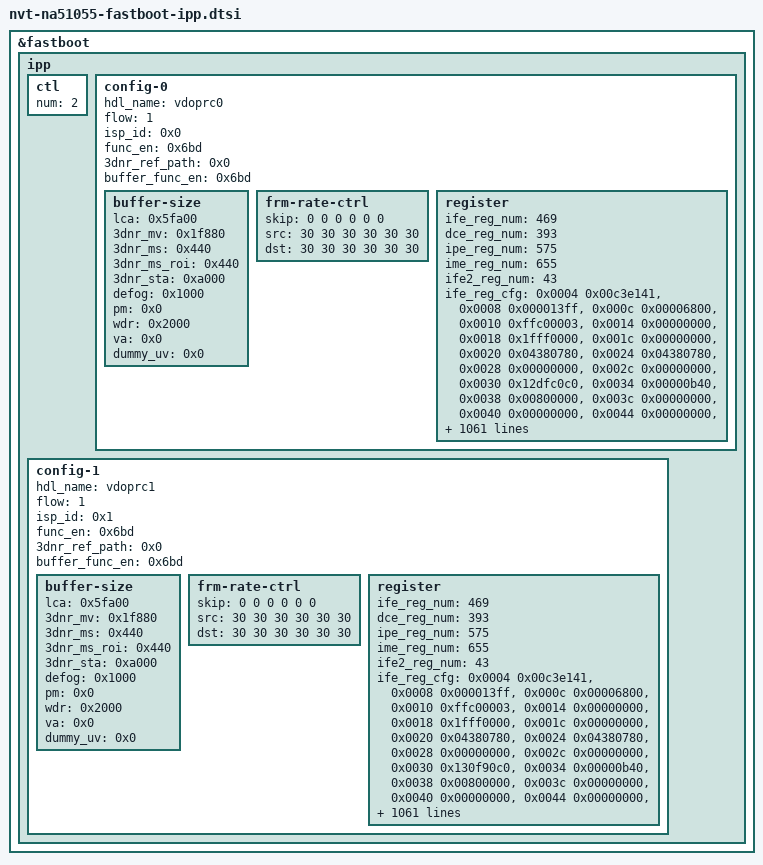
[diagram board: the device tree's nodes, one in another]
&fastboot {
	ipp {
		ctl {
			num = <2>;
		};
		config-0 {
			hdl_name = "vdoprc0";
			flow = <1>;
			isp_id = <0x0>;
			func_en = <0x6bd>;
			3dnr_ref_path = <0x0>;
			buffer_func_en = <0x6bd>;
			buffer-size {
				lca = <0x5fa00>;
				3dnr_mv = <0x1f880>;
				3dnr_ms = <0x440>;
				3dnr_ms_roi = <0x440>;
				3dnr_sta = <0xa000>;
				defog = <0x1000>;
				pm = <0x0>;
				wdr = <0x2000>;
				va = <0x0>;
				dummy_uv = <0x0>;
			};
			frm-rate-ctrl {
				skip = <0 0 0 0 0 0>;
				src = <30 30 30 30 30 30>;
				dst = <30 30 30 30 30 30>;
			};
			register {
			  ife_reg_num = <469>;
			  dce_reg_num = <393>;
			  ipe_reg_num = <575>;
			  ime_reg_num = <655>;
			  ife2_reg_num = <43>;

			  ife_reg_cfg = 
			    <0x0004 0x00c3e141>,
			    <0x0008 0x000013ff>,
			    <0x000c 0x00006800>,
			    <0x0010 0xffc00003>,
			    <0x0014 0x00000000>,
			    <0x0018 0x1fff0000>,
			    <0x001c 0x00000000>,
			    <0x0020 0x04380780>,
			    <0x0024 0x04380780>,
			    <0x0028 0x00000000>,
			    <0x002c 0x00000000>,
			    <0x0030 0x12dfc0c0>,
			    <0x0034 0x00000b40>,
			    <0x0038 0x00800000>,
			    <0x003c 0x00000000>,
			    <0x0040 0x00000000>,
			    <0x0044 0x00000000>,
			    <0x0048 0x00000000>,
			    <0x004c 0x00000000>,
			    <0x0050 0x00000000>,
			    <0x0054 0x00800000>,
			    <0x0058 0x00000000>,
			    <0x005c 0x00001000>,
			    <0x0060 0x00000000>,
			    <0x0064 0x00000000>,
			    <0x0068 0x00000000>,
			    <0x006c 0x00000000>,
			    <0x0070 0x000fff08>,
			    <0x0074 0x01120214>,
			    <0x0078 0x027b0112>,
			    <0x007c 0x00000112>,
			    <0x0080 0x00800080>,
			    <0x0084 0x00800080>,
			    <0x0088 0x00000080>,
			    <0x008c 0x00800080>,
			    <0x0090 0x00800080>,
			    <0x0094 0x00000080>,
			    <0x0098 0x00000000>,
			    <0x009c 0x00000000>,
			    <0x00a0 0x00000000>,
			    <0x00a4 0x00000000>,
			    <0x00a8 0x00000000>,
			    <0x00ac 0x00000000>,
			    <0x00b0 0x01000100>,
			    <0x00b4 0x01000100>,
			    <0x00b8 0x00000100>,
			    <0x00bc 0x00000000>,
			    <0x00c0 0x00000000>,
			    <0x00c4 0x00000000>,
			    <0x00c8 0x00000000>,
			    <0x00cc 0x00000000>,
			    <0x00d0 0x00000000>,
			    <0x00d4 0x00000000>,
			    <0x00d8 0x00000000>,
			    <0x00dc 0x00000000>,
			    <0x00e0 0x00000000>,
			    <0x00e4 0x00000000>,
			    <0x00e8 0x00000000>,
			    <0x00ec 0x00000000>,
			    <0x00f0 0x00000000>,
			    <0x00f4 0x00000000>,
			    <0x00f8 0x00000000>,
			    <0x00fc 0x00000000>,
			    <0x0100 0x00080040>,
			    <0x0104 0x00501200>,
			    <0x0108 0x0911171f>,
			    <0x010c 0x00000307>,
			    <0x0110 0x00010000>,
			    <0x0114 0x00020001>,
			    <0x0118 0x00030002>,
			    <0x011c 0x00000000>,
			    <0x0120 0x00010000>,
			    <0x0124 0x00020001>,
			    <0x0128 0x00030002>,
			    <0x012c 0x00000000>,
			    <0x0130 0x00010000>,
			    <0x0134 0x00020001>,
			    <0x0138 0x00030002>,
			    <0x013c 0x00000000>,
			    <0x0140 0x00010000>,
			    <0x0144 0x00020001>,
			    <0x0148 0x00030002>,
			    <0x014c 0x00000000>,
			    <0x0150 0x00020000>,
			    <0x0154 0x00040002>,
			    <0x0158 0x00060004>,
			    <0x015c 0x00000000>,
			    <0x0160 0x00020000>,
			    <0x0164 0x00040002>,
			    <0x0168 0x00060004>,
			    <0x016c 0x00000000>,
			    <0x0170 0x00020000>,
			    <0x0174 0x00040002>,
			    <0x0178 0x00060004>,
			    <0x017c 0x00000000>,
			    <0x0180 0x00020000>,
			    <0x0184 0x00040002>,
			    <0x0188 0x00060004>,
			    <0x018c 0x00000000>,
			    <0x0190 0x002c62c6>,
			    <0x0194 0x0040c40c>,
			    <0x0198 0x006af6af>,
			    <0x019c 0x0093d93d>,
			    <0x01a0 0x00f41f41>,
			    <0x01a4 0x00010000>,
			    <0x01a8 0x00010033>,
			    <0x01ac 0x86543210>,
			    <0x01b0 0x86543210>,
			    <0x01b4 0x00f00001>,
			    <0x01b8 0x008000a0>,
			    <0x01bc 0x000010ff>,
			    <0x01c0 0x00020000>,
			    <0x01c4 0x00030002>,
			    <0x01c8 0x00040004>,
			    <0x01cc 0x00050004>,
			    <0x01d0 0x00060005>,
			    <0x01d4 0x00060006>,
			    <0x01d8 0x00070006>,
			    <0x01dc 0x00070007>,
			    <0x01e0 0x00000008>,
			    <0x01e4 0x00020000>,
			    <0x01e8 0x00030002>,
			    <0x01ec 0x00040004>,
			    <0x01f0 0x00050004>,
			    <0x01f4 0x00060005>,
			    <0x01f8 0x00060006>,
			    <0x01fc 0x00070006>,
			    <0x0200 0x00070007>,
			    <0x0204 0x00000008>,
			    <0x0208 0x00020000>,
			    <0x020c 0x00030002>,
			    <0x0210 0x00040004>,
			    <0x0214 0x00050004>,
			    <0x0218 0x00060005>,
			    <0x021c 0x00060006>,
			    <0x0220 0x00070006>,
			    <0x0224 0x00070007>,
			    <0x0228 0x00000008>,
			    <0x022c 0x00020000>,
			    <0x0230 0x00030002>,
			    <0x0234 0x00040004>,
			    <0x0238 0x00050004>,
			    <0x023c 0x00060005>,
			    <0x0240 0x00060006>,
			    <0x0244 0x00070006>,
			    <0x0248 0x00070007>,
			    <0x024c 0x00000008>,
			    <0x0250 0x00040000>,
			    <0x0254 0x00060004>,
			    <0x0258 0x00080008>,
			    <0x025c 0x000a0008>,
			    <0x0260 0x000c000a>,
			    <0x0264 0x000c000c>,
			    <0x0268 0x000e000c>,
			    <0x026c 0x000e000e>,
			    <0x0270 0x00000010>,
			    <0x0274 0x00040000>,
			    <0x0278 0x00060004>,
			    <0x027c 0x00080008>,
			    <0x0280 0x000a0008>,
			    <0x0284 0x000c000a>,
			    <0x0288 0x000c000c>,
			    <0x028c 0x000e000c>,
			    <0x0290 0x000e000e>,
			    <0x0294 0x00000010>,
			    <0x0298 0x00040000>,
			    <0x029c 0x00060004>,
			    <0x02a0 0x00080008>,
			    <0x02a4 0x000a0008>,
			    <0x02a8 0x000c000a>,
			    <0x02ac 0x000c000c>,
			    <0x02b0 0x000e000c>,
			    <0x02b4 0x000e000e>,
			    <0x02b8 0x00000010>,
			    <0x02bc 0x00040000>,
			    <0x02c0 0x00060004>,
			    <0x02c4 0x00080008>,
			    <0x02c8 0x000a0008>,
			    <0x02cc 0x000c000a>,
			    <0x02d0 0x000c000c>,
			    <0x02d4 0x000e000c>,
			    <0x02d8 0x000e000e>,
			    <0x02dc 0x00000010>,
			    <0x02e0 0x021c03c0>,
			    <0x02e4 0x021c03c0>,
			    <0x02e8 0x021c03c0>,
			    <0x02ec 0x021c03c0>,
			    <0x02f0 0x003b73b8>,
			    <0x02f4 0x00000001>,
			    <0x02f8 0x00000000>,
			    <0x02fc 0x00000000>,
			    <0x0300 0x00000000>,
			    <0x0304 0x00000000>,
			    <0x0308 0x00000000>,
			    <0x030c 0x00000000>,
			    <0x0310 0x00000000>,
			    <0x0314 0x00000000>,
			    <0x0318 0x00000000>,
			    <0x031c 0x00000000>,
			    <0x0320 0x00000000>,
			    <0x0324 0x00000000>,
			    <0x0328 0x00000000>,
			    <0x032c 0x00000000>,
			    <0x0330 0x00000000>,
			    <0x0334 0x00000000>,
			    <0x0338 0x00000000>,
			    <0x033c 0x00000000>,
			    <0x0340 0x00000000>,
			    <0x0344 0x00000000>,
			    <0x0348 0x00000000>,
			    <0x034c 0x00000000>,
			    <0x0350 0x00000000>,
			    <0x0354 0x00000000>,
			    <0x0358 0x00000000>,
			    <0x035c 0x00000000>,
			    <0x0360 0x00000000>,
			    <0x0364 0x00000000>,
			    <0x0368 0x00000000>,
			    <0x036c 0x00000000>,
			    <0x0370 0x00000000>,
			    <0x0374 0x00000000>,
			    <0x0378 0x00000000>,
			    <0x037c 0x00000000>,
			    <0x0380 0x00000000>,
			    <0x0384 0x00000000>,
			    <0x0388 0x09060301>,
			    <0x038c 0x15120f0d>,
			    <0x0390 0x211e1b18>,
			    <0x0394 0x2d2a2724>,
			    <0x0398 0x00000030>,
			    <0x039c 0x1b181000>,
			    <0x03a0 0x1f1e1c1b>,
			    <0x03a4 0x1c1d1e1f>,
			    <0x03a8 0x0c1a1b1c>,
			    <0x03ac 0x00000004>,
			    <0x03b0 0x00000000>,
			    <0x03b4 0x00000000>,
			    <0x03b8 0x00000000>,
			    <0x03bc 0x00000000>,
			    <0x03c0 0x1f1f1f1f>,
			    <0x03c4 0x1e1e1f1f>,
			    <0x03c8 0x14181c1d>,
			    <0x03cc 0x080a0c10>,
			    <0x03d0 0x06060606>,
			    <0x03d4 0x05050505>,
			    <0x03d8 0x04040404>,
			    <0x03dc 0x20010203>,
			    <0x03e0 0x00000000>,
			    <0x03e4 0x00000000>,
			    <0x03e8 0x00000000>,
			    <0x03ec 0x00000000>,
			    <0x03f0 0x00000000>,
			    <0x03f4 0x00000000>,
			    <0x03f8 0x00000000>,
			    <0x03fc 0x00000000>,
			    <0x0400 0x00000000>,
			    <0x0404 0x00000000>,
			    <0x0408 0x00000000>,
			    <0x040c 0x01000000>,
			    <0x0410 0x00000000>,
			    <0x0414 0x00000000>,
			    <0x0418 0x00000000>,
			    <0x041c 0x01000000>,
			    <0x0420 0x00000000>,
			    <0x0424 0x00000000>,
			    <0x0428 0x00000000>,
			    <0x042c 0x00000000>,
			    <0x0430 0x00000000>,
			    <0x0434 0x00000000>,
			    <0x0438 0x00000000>,
			    <0x043c 0x00000000>,
			    <0x0440 0x00000000>,
			    <0x0444 0x00000000>,
			    <0x0448 0x00000000>,
			    <0x044c 0x00000000>,
			    <0x0450 0x00000000>,
			    <0x0454 0x00000000>,
			    <0x0458 0x00000000>,
			    <0x045c 0x00000000>,
			    <0x0460 0x00000000>,
			    <0x0464 0x00000000>,
			    <0x0468 0x00000000>,
			    <0x046c 0x00000000>,
			    <0x0470 0x00000000>,
			    <0x0474 0x00000000>,
			    <0x0478 0x00000000>,
			    <0x047c 0x00000000>,
			    <0x0480 0x00000000>,
			    <0x0484 0x00000000>,
			    <0x0488 0x00000000>,
			    <0x048c 0x00000000>,
			    <0x0490 0x00000000>,
			    <0x0494 0x00000000>,
			    <0x0498 0x00000000>,
			    <0x049c 0x00000000>,
			    <0x04a0 0x00000000>,
			    <0x04a4 0x00000000>,
			    <0x04a8 0x00000000>,
			    <0x04ac 0x00000000>,
			    <0x04b0 0x00000000>,
			    <0x04b4 0x00000000>,
			    <0x04b8 0x00000000>,
			    <0x04bc 0x00000000>,
			    <0x04c0 0x00000000>,
			    <0x04c4 0x00000000>,
			    <0x04c8 0x00000000>,
			    <0x04cc 0x00000000>,
			    <0x04d0 0x00000000>,
			    <0x04d4 0x00000000>,
			    <0x04d8 0x00000000>,
			    <0x04dc 0x00000000>,
			    <0x04e0 0x00000000>,
			    <0x04e4 0x00000000>,
			    <0x04e8 0x00000000>,
			    <0x04ec 0x00000000>,
			    <0x04f0 0x00000000>,
			    <0x04f4 0x00000000>,
			    <0x04f8 0x00000000>,
			    <0x04fc 0x00000000>,
			    <0x0500 0x00000000>,
			    <0x0504 0x00000000>,
			    <0x0508 0x00000000>,
			    <0x050c 0x00000000>,
			    <0x0510 0x00000000>,
			    <0x0514 0x00000000>,
			    <0x0518 0x00000000>,
			    <0x051c 0x00000000>,
			    <0x0520 0x00000000>,
			    <0x0524 0x00000000>,
			    <0x0528 0x00000000>,
			    <0x052c 0x00000000>,
			    <0x0530 0x00000000>,
			    <0x0534 0x00000000>,
			    <0x0538 0x00000000>,
			    <0x053c 0x00000000>,
			    <0x0540 0x00000000>,
			    <0x0544 0x00000000>,
			    <0x0548 0x00000000>,
			    <0x054c 0x00000000>,
			    <0x0550 0x00100210>,
			    <0x0554 0x0e009c00>,
			    <0x0558 0x810060c0>,
			    <0x055c 0x0e009c00>,
			    <0x0560 0x810060c0>,
			    <0x0564 0x00000000>,
			    <0x0568 0x00000000>,
			    <0x056c 0x00000000>,
			    <0x0570 0x00000100>,
			    <0x0574 0x18a41040>,
			    <0x0578 0x10a63a0e>,
			    <0x057c 0x00000886>,
			    <0x0580 0x18a41040>,
			    <0x0584 0x10a63a0e>,
			    <0x0588 0x00000886>,
			    <0x058c 0x00000000>,
			    <0x0590 0xff100fff>,
			    <0x0594 0xff100fff>,
			    <0x0598 0x00000000>,
			    <0x059c 0x00000000>,
			    <0x05a0 0x00400010>,
			    <0x05a4 0x00000100>,
			    <0x05a8 0x00400000>,
			    <0x05ac 0x04000100>,
			    <0x05b0 0x00002222>,
			    <0x05b4 0x00000000>,
			    <0x05b8 0x00000000>,
			    <0x05bc 0x00000000>,
			    <0x05c0 0x00000000>,
			    <0x05c4 0x00000000>,
			    <0x05c8 0x00000000>,
			    <0x05cc 0x00000000>,
			    <0x05d0 0x00000000>,
			    <0x05d4 0x00000000>,
			    <0x05d8 0x00000000>,
			    <0x05dc 0x00000000>,
			    <0x05e0 0x00000000>,
			    <0x05e4 0x00000000>,
			    <0x05e8 0x00000000>,
			    <0x05ec 0x00000000>,
			    <0x05f0 0x00000000>,
			    <0x05f4 0x00000000>,
			    <0x05f8 0x00000000>,
			    <0x05fc 0x00000000>,
			    <0x0600 0x00000004>,
			    <0x0604 0xffffffff>,
			    <0x0608 0x80a0c0e0>,
			    <0x060c 0x10204060>,
			    <0x0610 0x00000000>,
			    <0x0614 0x00000000>,
			    <0x0618 0x06040200>,
			    <0x061c 0x0e0c0a08>,
			    <0x0620 0x16141210>,
			    <0x0624 0x1e1c1a18>,
			    <0x0628 0x26242220>,
			    <0x062c 0x2e2c2a28>,
			    <0x0630 0x36343230>,
			    <0x0634 0x3e3c3a38>,
			    <0x0638 0x55555555>,
			    <0x063c 0x55555555>,
			    <0x0640 0x03430000>,
			    <0x0644 0x060604e9>,
			    <0x0648 0x078b06de>,
			    <0x064c 0x0898081c>,
			    <0x0650 0x09670905>,
			    <0x0654 0x0a0e09be>,
			    <0x0658 0x0a9b0a57>,
			    <0x065c 0x0b140ad9>,
			    <0x0660 0x0b7f0b4b>,
			    <0x0664 0x0bde0bb0>,
			    <0x0668 0x0c340c0a>,
			    <0x066c 0x0c830c5c>,
			    <0x0670 0x0ccb0ca8>,
			    <0x0674 0x0d0d0ced>,
			    <0x0678 0x0d4b0d2d>,
			    <0x067c 0x0d850d69>,
			    <0x0680 0x0dbc0da1>,
			    <0x0684 0x0def0dd6>,
			    <0x0688 0x0e200e08>,
			    <0x068c 0x0e4e0e37>,
			    <0x0690 0x0e790e64>,
			    <0x0694 0x0ea30e8e>,
			    <0x0698 0x0ecb0eb7>,
			    <0x069c 0x0ef10ede>,
			    <0x06a0 0x0f150f03>,
			    <0x06a4 0x0f380f27>,
			    <0x06a8 0x0f5a0f49>,
			    <0x06ac 0x0f7a0f6a>,
			    <0x06b0 0x0f9a0f8a>,
			    <0x06b4 0x0fb80fa9>,
			    <0x06b8 0x0fd50fc7>,
			    <0x06bc 0x0ff20fe4>,
			    <0x06c0 0x00000fff>,
			    <0x06c4 0x00000000>,
			    <0x06c8 0x00000000>,
			    <0x06cc 0x00000000>,
			    <0x06d0 0x00000000>,
			    <0x06d4 0x00000000>,
			    <0x06d8 0x00000000>,
			    <0x06dc 0x00000000>,
			    <0x06e0 0x00000000>,
			    <0x06e4 0x00000000>,
			    <0x06e8 0x00000000>,
			    <0x06ec 0x00000000>,
			    <0x06f0 0x00000000>,
			    <0x06f4 0x00000000>,
			    <0x06f8 0x00000000>,
			    <0x06fc 0x00000000>,
			    <0x0700 0x00000011>,
			    <0x0704 0x0c080400>,
			    <0x0708 0x1c181410>,
			    <0x070c 0x0002aaaa>,
			    <0x0710 0x0002aaaa>,
			    <0x0714 0x00200000>,
			    <0x0718 0x00600040>,
			    <0x071c 0x00a00080>,
			    <0x0720 0x00e000c0>,
			    <0x0724 0x01440100>,
			    <0x0728 0x01e40190>,
			    <0x072c 0x02a40240>,
			    <0x0730 0x03840310>,
			    <0x0734 0x04840400>,
			    <0x0738 0x05a40510>,
			    <0x073c 0x06e40640>,
			    <0x0740 0x08440790>,
			    <0x0744 0x09c40900>,
			    <0x0748 0x0b640a90>,
			    <0x074c 0x0d240c40>,
			    <0x0750 0x0f040e10>,
			    <0x0754 0x00000fff>;

			  dce_reg_cfg = 
			    <0x0004 0x00004614>,
			    <0x0008 0x00001fdf>,
			    <0x000c 0x00000000>,
			    <0x0010 0x04380780>,
			    <0x0014 0x00000000>,
			    <0x0018 0x00000010>,
			    <0x001c 0x00400000>,
			    <0x0020 0x00400000>,
			    <0x0024 0x00000780>,
			    <0x0028 0x00400000>,
			    <0x002c 0x00000780>,
			    <0x0030 0x00400000>,
			    <0x0034 0x00000780>,
			    <0x0038 0x00400000>,
			    <0x003c 0x00000780>,
			    <0x0040 0x00000021>,
			    <0x0044 0x11244912>,
			    <0x0048 0x11244912>,
			    <0x004c 0x0f23c912>,
			    <0x0050 0x0f23c8f2>,
			    <0x0054 0x0f23c8f2>,
			    <0x0058 0x000000f2>,
			    <0x005c 0x7f340000>,
			    <0x0060 0x00000000>,
			    <0x0064 0x044f0000>,
			    <0x0068 0x044f0000>,
			    <0x006c 0x00000012>,
			    <0x0070 0x00000000>,
			    <0x0074 0x00000000>,
			    <0x0078 0x00000000>,
			    <0x007c 0x00000000>,
			    <0x0080 0x00000000>,
			    <0x0084 0x00000000>,
			    <0x0088 0x00000000>,
			    <0x008c 0x00000780>,
			    <0x0090 0x00000000>,
			    <0x0094 0x00000000>,
			    <0x0098 0x00000000>,
			    <0x009c 0x00000000>,
			    <0x00a0 0x00000000>,
			    <0x00a4 0x00400000>,
			    <0x00a8 0x2c0003c0>,
			    <0x00ac 0x000a0028>,
			    <0x00b0 0x80000000>,
			    <0x00b4 0x00000000>,
			    <0x00b8 0xf8888888>,
			    <0x00bc 0x485f7880>,
			    <0x00c0 0x2428303a>,
			    <0x00c4 0x20202020>,
			    <0x00c8 0x20202020>,
			    <0x00cc 0x00a00020>,
			    <0x00d0 0x00014008>,
			    <0x00d4 0x122347ff>,
			    <0x00d8 0x00000111>,
			    <0x00dc 0x00000000>,
			    <0x00e0 0x40081007>,
			    <0x00e4 0x00408003>,
			    <0x00e8 0x00cc00cc>,
			    <0x00ec 0xa80080e6>,
			    <0x00f0 0x00800080>,
			    <0x00f4 0x00010080>,
			    <0x00f8 0x00000100>,
			    <0x00fc 0xffffe0c0>,
			    <0x0100 0x00000000>,
			    <0x0104 0x00000000>,
			    <0x0108 0x00000000>,
			    <0x010c 0x00000000>,
			    <0x0110 0x00000000>,
			    <0x0114 0x00000000>,
			    <0x0118 0x00000000>,
			    <0x011c 0x00000000>,
			    <0x0120 0x0000023f>,
			    <0x0124 0x16240600>,
			    <0x0128 0x00000100>,
			    <0x012c 0x16242600>,
			    <0x0130 0x00000100>,
			    <0x0134 0x04080422>,
			    <0x0138 0x0f79cc3b>,
			    <0x013c 0x0fde1c3b>,
			    <0x0140 0x00000000>,
			    <0x0144 0x00000000>,
			    <0x0148 0x00000000>,
			    <0x014c 0x00000000>,
			    <0x0150 0x00000000>,
			    <0x0154 0x20000000>,
			    <0x0158 0x00000054>,
			    <0x015c 0x1565193c>,
			    <0x0160 0x160c160c>,
			    <0x0164 0x05030003>,
			    <0x0168 0x00000000>,
			    <0x016c 0x00000000>,
			    <0x0170 0x00000000>,
			    <0x0174 0x00000000>,
			    <0x0178 0x00000000>,
			    <0x017c 0x00000000>,
			    <0x0180 0x00000000>,
			    <0x0184 0x00000000>,
			    <0x0188 0x00000000>,
			    <0x018c 0x00000000>,
			    <0x0190 0x00000000>,
			    <0x0194 0x00000000>,
			    <0x0198 0x00000000>,
			    <0x019c 0x00000000>,
			    <0x01a0 0x00000000>,
			    <0x01a4 0x00000000>,
			    <0x01a8 0x00000000>,
			    <0x01ac 0x00000000>,
			    <0x01b0 0x00000000>,
			    <0x01b4 0x00000000>,
			    <0x01b8 0x00000000>,
			    <0x01bc 0x00000000>,
			    <0x01c0 0x00000000>,
			    <0x01c4 0x00000000>,
			    <0x01c8 0x00000000>,
			    <0x01cc 0x00000000>,
			    <0x01d0 0x00000000>,
			    <0x01d4 0x00000000>,
			    <0x01d8 0x00000000>,
			    <0x01dc 0x00000000>,
			    <0x01e0 0x00000000>,
			    <0x01e4 0x00000000>,
			    <0x01e8 0x00000000>,
			    <0x01ec 0x00000000>,
			    <0x01f0 0x00000000>,
			    <0x01f4 0x00000000>,
			    <0x01f8 0x00000000>,
			    <0x01fc 0x00000000>,
			    <0x0200 0x00000000>,
			    <0x0204 0x00000000>,
			    <0x0208 0x00000000>,
			    <0x020c 0x00000000>,
			    <0x0210 0x00000000>,
			    <0x0214 0x18100800>,
			    <0x0218 0x2624201c>,
			    <0x021c 0x2b2a2928>,
			    <0x0220 0x2f2e2d2c>,
			    <0x0224 0x33323130>,
			    <0x0228 0x37363534>,
			    <0x022c 0x3b3a3938>,
			    <0x0230 0x3f3e3d3c>,
			    <0x0234 0x00005abf>,
			    <0x0238 0x00000000>,
			    <0x023c 0x0ff70fff>,
			    <0x0240 0x0fa10fd8>,
			    <0x0244 0x0ef10f54>,
			    <0x0248 0x0df70e7b>,
			    <0x024c 0x0cd10d68>,
			    <0x0250 0x0b9d0c37>,
			    <0x0254 0x0a700b04>,
			    <0x0258 0x095909e1>,
			    <0x025c 0x085f08d8>,
			    <0x0260 0x078407ee>,
			    <0x0264 0x06c70722>,
			    <0x0268 0x06240673>,
			    <0x026c 0x055c05dc>,
			    <0x0270 0x049004ee>,
			    <0x0274 0x03f9043f>,
			    <0x0278 0x038803bd>,
			    <0x027c 0x0332035b>,
			    <0x0280 0x02f0030f>,
			    <0x0284 0x02a602d4>,
			    <0x0288 0x02620280>,
			    <0x028c 0x02230249>,
			    <0x0290 0x01f30208>,
			    <0x0294 0x01d801e4>,
			    <0x0298 0x01c801cf>,
			    <0x029c 0x01bd01c2>,
			    <0x02a0 0x01b501b9>,
			    <0x02a4 0x01b001b2>,
			    <0x02a8 0x01ac01ae>,
			    <0x02ac 0x01a901aa>,
			    <0x02b0 0x01a601a7>,
			    <0x02b4 0x01a401a5>,
			    <0x02b8 0x01a301a4>,
			    <0x02bc 0x000001a2>,
			    <0x02c0 0x00008040>,
			    <0x02c4 0xffff0000>,
			    <0x02c8 0x00000000>,
			    <0x02cc 0x00000000>,
			    <0x02d0 0x00000000>,
			    <0x02d4 0x79420000>,
			    <0x02d8 0x6ffcbb81>,
			    <0x02dc 0xb14f698a>,
			    <0x02e0 0xb79eb2e2>,
			    <0x02e4 0x92217cf2>,
			    <0x02e8 0x6d6369e8>,
			    <0x02ec 0x64d75e86>,
			    <0x02f0 0x6e7d641f>,
			    <0x02f4 0xa7c59e69>,
			    <0x02f8 0x9064c26e>,
			    <0x02fc 0x5a11634c>,
			    <0x0300 0x4e5c54cc>,
			    <0x0304 0x57365098>,
			    <0x0308 0x4d795284>,
			    <0x030c 0x591a4c7a>,
			    <0x0310 0x5ad85ff0>,
			    <0x0314 0x58d05719>,
			    <0x0318 0x565655c9>,
			    <0x031c 0x544e57b1>,
			    <0x0320 0x530257ca>,
			    <0x0324 0x4a054b4d>,
			    <0x0328 0x5c71539f>,
			    <0x032c 0x5e6267d3>,
			    <0x0330 0x737d64dc>,
			    <0x0334 0x5ff57876>,
			    <0x0338 0x472d4c5e>,
			    <0x033c 0x44e54e0b>,
			    <0x0340 0x401d3e8d>,
			    <0x0344 0x45df4627>,
			    <0x0348 0x2e1539c8>,
			    <0x034c 0x2409264a>,
			    <0x0350 0x24d125c6>,
			    <0x0354 0x260b23de>,
			    <0x0358 0x2b4029ba>,
			    <0x035c 0x2db32cc5>,
			    <0x0360 0x342d2c04>,
			    <0x0364 0x432d3a45>,
			    <0x0368 0x53c753ac>,
			    <0x036c 0x4f1347b3>,
			    <0x0370 0x5788573a>,
			    <0x0374 0x55856142>,
			    <0x0378 0x510f5229>,
			    <0x037c 0x3c904d84>,
			    <0x0380 0x2cb3312c>,
			    <0x0384 0x24a32969>,
			    <0x0388 0x18fe1f4e>,
			    <0x038c 0x16ff16ed>,
			    <0x0390 0x19e91902>,
			    <0x0394 0x1675182e>,
			    <0x0398 0x095c0f8f>,
			    <0x039c 0x06f6078e>,
			    <0x03a0 0x0561059e>,
			    <0x03a4 0x04a7053f>,
			    <0x03a8 0x044e0447>,
			    <0x03ac 0x0490046a>,
			    <0x03b0 0x041c04b3>,
			    <0x03b4 0x02fd0407>,
			    <0x03b8 0x02970274>,
			    <0x03bc 0x02510292>,
			    <0x03c0 0x025e0271>,
			    <0x03c4 0x02d0021f>,
			    <0x03c8 0x056b0365>,
			    <0x03cc 0x032f04ba>,
			    <0x03d0 0x1cac0441>,
			    <0x03d4 0x00000000>,
			    <0x03d8 0x00000000>,
			    <0x03dc 0x00000000>,
			    <0x03e0 0x00000000>,
			    <0x03e4 0x00000000>,
			    <0x03e8 0x00000000>,
			    <0x03ec 0x00000000>,
			    <0x03f0 0x00000000>,
			    <0x03f4 0x00000000>,
			    <0x03f8 0x00000000>,
			    <0x03fc 0x00000000>,
			    <0x0400 0x00000000>,
			    <0x0404 0x00000000>,
			    <0x0408 0x00ffffff>,
			    <0x040c 0x037415dd>,
			    <0x0410 0x00000000>,
			    <0x0414 0x00000000>,
			    <0x0418 0x10001000>,
			    <0x041c 0x00001000>,
			    <0x0420 0x00000000>,
			    <0x0424 0x00000000>,
			    <0x0428 0x00000000>,
			    <0x042c 0x00000000>,
			    <0x0430 0x00000000>,
			    <0x0434 0x00000000>,
			    <0x0438 0x00000000>,
			    <0x043c 0x00000000>,
			    <0x0440 0xfe0bffff>,
			    <0x0444 0xfa62fc2d>,
			    <0x0448 0xf704f8aa>,
			    <0x044c 0xf3e4f56d>,
			    <0x0450 0xf0fcf26a>,
			    <0x0454 0xee43ef9a>,
			    <0x0458 0xebb4ecf7>,
			    <0x045c 0xe94bea7b>,
			    <0x0460 0xe703e823>,
			    <0x0464 0xe4dae5eb>,
			    <0x0468 0xe2cbe3cf>,
			    <0x046c 0xe0d6e1ce>,
			    <0x0470 0xdef7dfe4>,
			    <0x0474 0xdd2cde0f>,
			    <0x0478 0xdb75dc4f>,
			    <0x047c 0xd9d0daa0>,
			    <0x0480 0xd83ad903>,
			    <0x0484 0xd6b4d775>,
			    <0x0488 0xd53cd5f6>,
			    <0x048c 0xd3d1d485>,
			    <0x0490 0xd272d320>,
			    <0x0494 0xd11fd1c7>,
			    <0x0498 0xcfd6d079>,
			    <0x049c 0xce98cf36>,
			    <0x04a0 0xcd63cdfc>,
			    <0x04a4 0xcc38cccc>,
			    <0x04a8 0xcb15cba5>,
			    <0x04ac 0xc9faca86>,
			    <0x04b0 0xc8e6c96f>,
			    <0x04b4 0xc7dac860>,
			    <0x04b8 0xc6d5c757>,
			    <0x04bc 0xc5d7c655>,
			    <0x04c0 0x0000c599>,
			    <0x04c4 0x00000000>,
			    <0x04c8 0x00000000>,
			    <0x04cc 0x00000000>,
			    <0x04d0 0x00000000>,
			    <0x04d4 0x00000000>,
			    <0x04d8 0x00000000>,
			    <0x04dc 0x00000000>,
			    <0x04e0 0x00000000>,
			    <0x04e4 0x00000000>,
			    <0x04e8 0x00000000>,
			    <0x04ec 0x00000000>,
			    <0x04f0 0x00000000>,
			    <0x04f4 0x00000000>,
			    <0x04f8 0x00000000>,
			    <0x04fc 0x00000000>,
			    <0x0500 0x00000000>,
			    <0x0504 0x00000000>,
			    <0x0508 0x00000000>,
			    <0x050c 0x00000000>,
			    <0x0510 0x00000000>,
			    <0x0514 0x00000000>,
			    <0x0518 0x00000000>,
			    <0x051c 0x00000000>,
			    <0x0520 0x00000000>,
			    <0x0524 0x00000000>,
			    <0x0528 0x00000000>,
			    <0x052c 0x00000000>,
			    <0x0530 0x00000000>,
			    <0x0534 0x00000000>,
			    <0x0538 0x00000000>,
			    <0x053c 0x00000000>,
			    <0x0540 0x00000000>,
			    <0x0544 0x00000000>,
			    <0x0548 0x00000000>,
			    <0x054c 0x00000000>,
			    <0x0550 0x00000000>,
			    <0x0554 0x00000000>,
			    <0x0558 0x00000000>,
			    <0x055c 0x00000000>,
			    <0x0560 0x00000000>,
			    <0x0564 0x00000000>,
			    <0x0568 0x00000000>,
			    <0x056c 0x00000000>,
			    <0x0570 0x00000000>,
			    <0x0574 0x00000000>,
			    <0x0578 0x00000000>,
			    <0x057c 0x00000000>,
			    <0x0580 0x00000000>,
			    <0x0584 0x00000000>,
			    <0x0588 0x00000000>,
			    <0x058c 0x00000000>,
			    <0x0590 0x00000000>,
			    <0x0594 0x00000000>,
			    <0x0598 0x00000000>,
			    <0x059c 0x00000000>,
			    <0x05a0 0x00000000>,
			    <0x05a4 0x00000000>,
			    <0x05a8 0x00000000>,
			    <0x05ac 0x00000000>,
			    <0x05b0 0x00000000>,
			    <0x05b4 0x00000000>,
			    <0x05b8 0x00000000>,
			    <0x05bc 0x00000000>,
			    <0x05c0 0x00000000>,
			    <0x05c4 0x00000000>,
			    <0x05c8 0x00000000>,
			    <0x05cc 0x00000000>,
			    <0x05d0 0x00000000>,
			    <0x05d4 0x00000000>,
			    <0x05d8 0x00000000>,
			    <0x05dc 0x00000000>,
			    <0x05e0 0x00000000>,
			    <0x05e4 0x00000000>,
			    <0x05e8 0x00000000>,
			    <0x05ec 0x00000000>,
			    <0x05f0 0x00400000>,
			    <0x05f4 0x00000000>,
			    <0x05f8 0x00000000>,
			    <0x05fc 0x00000000>,
			    <0x0600 0x00000000>,
			    <0x0604 0x00000000>,
			    <0x0608 0x00000000>,
			    <0x060c 0x00000000>,
			    <0x0610 0x20191230>,
			    <0x0614 0x00000000>,
			    <0x0618 0x00000000>,
			    <0x061c 0x00000000>,
			    <0x0620 0x00000000>,
			    <0x0624 0x00000000>;

			  ipe_reg_cfg = 
			    <0x0004 0x08000005>,
			    <0x0008 0x00017edb>,
			    <0x000c 0x00000010>,
			    <0x0010 0x00000000>,
			    <0x0014 0x001e0000>,
			    <0x0018 0x00000438>,
			    <0x001c 0x00000000>,
			    <0x0020 0x00000000>,
			    <0x0024 0x00000000>,
			    <0x0028 0x00000000>,
			    <0x002c 0x160dd428>,
			    <0x0030 0x00000000>,
			    <0x0034 0x00000000>,
			    <0x0038 0x00800000>,
			    <0x003c 0x00800000>,
			    <0x0040 0x00000000>,
			    <0x0044 0x00000000>,
			    <0x0048 0x10000000>,
			    <0x004c 0x00000000>,
			    <0x0050 0x00001ffe>,
			    <0x0054 0x00000000>,
			    <0x0058 0xff040001>,
			    <0x005c 0x00000000>,
			    <0x0060 0x00000000>,
			    <0x0064 0x00000000>,
			    <0x0068 0x00000000>,
			    <0x006c 0x00000000>,
			    <0x0070 0x017c05a3>,
			    <0x0074 0x3e2ec02a>,
			    <0x0078 0x00a013dd>,
			    <0x007c 0x0010100a>,
			    <0x0080 0x00181818>,
			    <0x0084 0x00000333>,
			    <0x0088 0x00010004>,
			    <0x008c 0x00008888>,
			    <0x0090 0x88881000>,
			    <0x0094 0x00082028>,
			    <0x0098 0xffc8201f>,
			    <0x009c 0x00a500b6>,
			    <0x00a0 0x00800801>,
			    <0x00a4 0xffff3180>,
			    <0x00a8 0x00010000>,
			    <0x00ac 0x01000100>,
			    <0x00b0 0x00600060>,
			    <0x00b4 0x05080000>,
			    <0x00b8 0x40352d20>,
			    <0x00bc 0x40404040>,
			    <0x00c0 0x40404040>,
			    <0x00c4 0x262c3440>,
			    <0x00c8 0x15020000>,
			    <0x00cc 0x7a573000>,
			    <0x00d0 0xffddb79a>,
			    <0x00d4 0xaac0e0ff>,
			    <0x00d8 0x8088909a>,
			    <0x00dc 0x03adc7ff>,
			    <0x00e0 0x40400001>,
			    <0x00e4 0x00000000>,
			    <0x00e8 0x00004040>,
			    <0x00ec 0x00000000>,
			    <0x00f0 0x41000804>,
			    <0x00f4 0x41000804>,
			    <0x00f8 0x41000804>,
			    <0x00fc 0x00000000>,
			    <0x0100 0x01b30001>,
			    <0x0104 0x0fe70f66>,
			    <0x0108 0x01840f9d>,
			    <0x010c 0x00290fdf>,
			    <0x0110 0x01e90eed>,
			    <0x0114 0x00104080>,
			    <0x0118 0x00000000>,
			    <0x011c 0x00000000>,
			    <0x0120 0x00000000>,
			    <0x0124 0x050a0f14>,
			    <0x0128 0x00000000>,
			    <0x012c 0x00000000>,
			    <0x0130 0x0f0a0500>,
			    <0x0134 0x00000000>,
			    <0x0138 0x00752c4d>,
			    <0x013c 0x120357d5>,
			    <0x0140 0x07af2a80>,
			    <0x0144 0x00000000>,
			    <0x0148 0x28200000>,
			    <0x014c 0x80808080>,
			    <0x0150 0x80808080>,
			    <0x0154 0x80808080>,
			    <0x0158 0x80808080>,
			    <0x015c 0x80808080>,
			    <0x0160 0x80808080>,
			    <0x0164 0x00000000>,
			    <0x0168 0x00000000>,
			    <0x016c 0x00000000>,
			    <0x0170 0x00000000>,
			    <0x0174 0x00000000>,
			    <0x0178 0x00000000>,
			    <0x017c 0x00000000>,
			    <0x0180 0x00000000>,
			    <0x0184 0x00000000>,
			    <0x0188 0x00000000>,
			    <0x018c 0x00000000>,
			    <0x0190 0x00000000>,
			    <0x0194 0x80808080>,
			    <0x0198 0x80808080>,
			    <0x019c 0x80808080>,
			    <0x01a0 0x80808080>,
			    <0x01a4 0x80808080>,
			    <0x01a8 0x80808080>,
			    <0x01ac 0x00820820>,
			    <0x01b0 0x00820820>,
			    <0x01b4 0x00000000>,
			    <0x01b8 0x0002308c>,
			    <0x01bc 0x00000080>,
			    <0x01c0 0x00000000>,
			    <0x01c4 0x00000000>,
			    <0x01c8 0x00ffffff>,
			    <0x01cc 0x00808080>,
			    <0x01d0 0x80808080>,
			    <0x01d4 0x00000000>,
			    <0x01d8 0x00000000>,
			    <0x01dc 0x08020080>,
			    <0x01e0 0x08020080>,
			    <0x01e4 0x08020080>,
			    <0x01e8 0x08020080>,
			    <0x01ec 0x08020080>,
			    <0x01f0 0x00020080>,
			    <0x01f4 0x00000000>,
			    <0x01f8 0x00000000>,
			    <0x01fc 0x00000000>,
			    <0x0200 0x00000000>,
			    <0x0204 0x00000000>,
			    <0x0208 0x00000000>,
			    <0x020c 0x00000000>,
			    <0x0210 0x00000000>,
			    <0x0214 0x00000000>,
			    <0x0218 0x00000000>,
			    <0x021c 0x00000000>,
			    <0x0220 0x00000000>,
			    <0x0224 0x00000000>,
			    <0x0228 0x00000000>,
			    <0x022c 0x00000000>,
			    <0x0230 0x00000000>,
			    <0x0234 0x00000000>,
			    <0x0238 0x00000000>,
			    <0x023c 0x00000000>,
			    <0x0240 0x00000000>,
			    <0x0244 0x00000000>,
			    <0x0248 0x00000000>,
			    <0x024c 0x00000000>,
			    <0x0250 0x00000000>,
			    <0x0254 0x00000000>,
			    <0x0258 0x00000000>,
			    <0x025c 0x00000000>,
			    <0x0260 0x00000000>,
			    <0x0264 0x00000000>,
			    <0x0268 0x00000000>,
			    <0x026c 0x00000000>,
			    <0x0270 0x00000000>,
			    <0x0274 0x00000000>,
			    <0x0278 0x00000000>,
			    <0x027c 0x00000000>,
			    <0x0280 0x00000000>,
			    <0x0284 0x00000000>,
			    <0x0288 0x00000000>,
			    <0x028c 0x00000000>,
			    <0x0290 0x00000000>,
			    <0x0294 0x00000000>,
			    <0x0298 0x00000000>,
			    <0x029c 0x00000000>,
			    <0x02a0 0x00000000>,
			    <0x02a4 0x00000000>,
			    <0x02a8 0x00000000>,
			    <0x02ac 0x00000000>,
			    <0x02b0 0x00000000>,
			    <0x02b4 0x00000000>,
			    <0x02b8 0x00000000>,
			    <0x02bc 0x00000000>,
			    <0x02c0 0x0000010f>,
			    <0x02c4 0x1623e600>,
			    <0x02c8 0x00000040>,
			    <0x02cc 0x1623f600>,
			    <0x02d0 0x00000040>,
			    <0x02d4 0x01e50200>,
			    <0x02d8 0x1ffbb877>,
			    <0x02dc 0x21b80077>,
			    <0x02e0 0x00000000>,
			    <0x02e4 0x00000000>,
			    <0x02e8 0x00000000>,
			    <0x02ec 0x00000000>,
			    <0x02f0 0x00000054>,
			    <0x02f4 0x00000000>,
			    <0x02f8 0x00000000>,
			    <0x02fc 0x00000000>,
			    <0x0300 0x00000000>,
			    <0x0304 0x00000000>,
			    <0x0308 0x00000000>,
			    <0x030c 0x00000000>,
			    <0x0310 0x00000000>,
			    <0x0314 0x00000000>,
			    <0x0318 0x00000000>,
			    <0x031c 0x00000000>,
			    <0x0320 0x00000000>,
			    <0x0324 0x00000000>,
			    <0x0328 0x00000000>,
			    <0x032c 0x00000000>,
			    <0x0330 0x00000000>,
			    <0x0334 0x00000000>,
			    <0x0338 0x00000000>,
			    <0x033c 0x00000818>,
			    <0x0340 0x00000000>,
			    <0x0344 0x00000000>,
			    <0x0348 0x00000000>,
			    <0x034c 0x00000000>,
			    <0x0350 0x00000000>,
			    <0x0354 0x00000000>,
			    <0x0358 0x0ff200ff>,
			    <0x035c 0x000000ff>,
			    <0x0360 0x00000000>,
			    <0x0364 0x00000000>,
			    <0x0368 0x00000000>,
			    <0x036c 0x00000000>,
			    <0x0370 0x00000000>,
			    <0x0374 0x00000000>,
			    <0x0378 0x00000000>,
			    <0x037c 0x00000000>,
			    <0x0380 0x00000000>,
			    <0x0384 0x00800000>,
			    <0x0388 0x54545454>,
			    <0x038c 0x54545454>,
			    <0x0390 0x00000054>,
			    <0x0394 0x00000000>,
			    <0x0398 0x00000000>,
			    <0x039c 0x00000000>,
			    <0x03a0 0x00e00004>,
			    <0x03a4 0x4000d200>,
			    <0x03a8 0x00000000>,
			    <0x03ac 0x00000000>,
			    <0x03b0 0x00000000>,
			    <0x03b4 0x00000000>,
			    <0x03b8 0x00000000>,
			    <0x03bc 0x00000000>,
			    <0x03c0 0x00000000>,
			    <0x03c4 0x00000000>,
			    <0x03c8 0x00000000>,
			    <0x03cc 0x00000000>,
			    <0x03d0 0x00000000>,
			    <0x03d4 0x00000000>,
			    <0x03d8 0x00000000>,
			    <0x03dc 0x00000000>,
			    <0x03e0 0x00000000>,
			    <0x03e4 0x00000000>,
			    <0x03e8 0x00000000>,
			    <0x03ec 0x00000000>,
			    <0x03f0 0x00000000>,
			    <0x03f4 0x00000000>,
			    <0x03f8 0x00000000>,
			    <0x03fc 0x00000000>,
			    <0x0400 0x1fe7d9ed>,
			    <0x0404 0x26d99a5f>,
			    <0x0408 0x1825d568>,
			    <0x040c 0x111404f1>,
			    <0x0410 0x1fe7d9ed>,
			    <0x0414 0x0f1384c6>,
			    <0x0418 0x2ffbeaf4>,
			    <0x041c 0x22988a1b>,
			    <0x0420 0x111404f1>,
			    <0x0424 0x2f4bbae8>,
			    <0x0428 0x25f96652>,
			    <0x042c 0x25292e44>,
			    <0x0430 0x38ce2384>,
			    <0x0434 0x111404f1>,
			    <0x0438 0x1db745c7>,
			    <0x043c 0x16856d4d>,
			    <0x0440 0x25f96652>,
			    <0x0444 0x1ed791db>,
			    <0x0448 0x27a9ce6d>,
			    <0x044c 0x21b8520d>,
			    <0x0450 0x1825d568>,
			    <0x0454 0x31dc6313>,
			    <0x0458 0x1825d568>,
			    <0x045c 0x25292e44>,
			    <0x0460 0x14d4f930>,
			    <0x0464 0x2ddb5ed1>,
			    <0x0468 0x14d4f930>,
			    <0x046c 0x26d99a5f>,
			    <0x0470 0x14d4f930>,
			    <0x0474 0x1fe7d9ed>,
			    <0x0478 0x2368c229>,
			    <0x047c 0x372db768>,
			    <0x0480 0x1fe7d9ed>,
			    <0x0484 0x3b7ecfaf>,
			    <0x0488 0x1db745c7>,
			    <0x048c 0x31dc6313>,
			    <0x0490 0x1b16999b>,
			    <0x0494 0x0f1384c6>,
			    <0x0498 0x1b16999b>,
			    <0x049c 0x111404f1>,
			    <0x04a0 0x33acd730>,
			    <0x04a4 0x111404f1>,
			    <0x04a8 0x2368c229>,
			    <0x04ac 0x20d819fe>,
			    <0x04b0 0x293a3687>,
			    <0x04b4 0x2aca9aa0>,
			    <0x04b8 0x1fe7d9ed>,
			    <0x04bc 0x309c12ff>,
			    <0x04c0 0x0f1384c6>,
			    <0x04c4 0x368d935f>,
			    <0x04c8 0x0f1384c6>,
			    <0x04cc 0x1ed791db>,
			    <0x04d0 0x111404f1>,
			    <0x04d4 0x2a0a6a93>,
			    <0x04d8 0x1825d568>,
			    <0x04dc 0x20d819fe>,
			    <0x04e0 0x2448f636>,
			    <0x04e4 0x1db745c7>,
			    <0x04e8 0x1db745c7>,
			    <0x04ec 0x330caf26>,
			    <0x04f0 0x21b8520d>,
			    <0x04f4 0x35fd6f56>,
			    <0x04f8 0x2448f636>,
			    <0x04fc 0x111404f1>,
			    <0x0500 0x2368c229>,
			    <0x0504 0x1825d568>,
			    <0x0508 0x1c76f1b1>,
			    <0x050c 0x20d819fe>,
			    <0x0510 0x2368c229>,
			    <0x0514 0x1b16999b>,
			    <0x0518 0x1c76f1b1>,
			    <0x051c 0x19b63d82>,
			    <0x0520 0x1b16999b>,
			    <0x0524 0x1ed791db>,
			    <0x0528 0x14d4f930>,
			    <0x052c 0x2a0a6a93>,
			    <0x0530 0x13048511>,
			    <0x0534 0x20d819fe>,
			    <0x0538 0x19b63d82>,
			    <0x053c 0x21b8520d>,
			    <0x0540 0x1825d568>,
			    <0x0544 0x1db745c7>,
			    <0x0548 0x19b63d82>,
			    <0x054c 0x1db745c7>,
			    <0x0550 0x1fe7d9ed>,
			    <0x0554 0x287a027a>,
			    <0x0558 0x2368c229>,
			    <0x055c 0x14d4f930>,
			    <0x0560 0x21b8520d>,
			    <0x0564 0x14d4f930>,
			    <0x0568 0x2b9aceac>,
			    <0x056c 0x14d4f930>,
			    <0x0570 0x27a9ce6d>,
			    <0x0574 0x1825d568>,
			    <0x0578 0x25f96652>,
			    <0x057c 0x21b8520d>,
			    <0x0580 0x2ddb5ed1>,
			    <0x0584 0x1db745c7>,
			    <0x0588 0x21b8520d>,
			    <0x058c 0x1db745c7>,
			    <0x0590 0x14d4f930>,
			    <0x0594 0x1ed791db>,
			    <0x0598 0x14d4f930>,
			    <0x059c 0x2448f636>,
			    <0x05a0 0x16856d4d>,
			    <0x05a4 0x2448f636>,
			    <0x05a8 0x1825d568>,
			    <0x05ac 0x287a027a>,
			    <0x05b0 0x1c76f1b1>,
			    <0x05b4 0x19b63d82>,
			    <0x05b8 0x1ed791db>,
			    <0x05bc 0x2368c229>,
			    <0x05c0 0x22988a1b>,
			    <0x05c4 0x14d4f930>,
			    <0x05c8 0x1c76f1b1>,
			    <0x05cc 0x14d4f930>,
			    <0x05d0 0x1fe7d9ed>,
			    <0x05d4 0x1825d568>,
			    <0x05d8 0x19b63d82>,
			    <0x05dc 0x1c76f1b1>,
			    <0x05e0 0x37bddb72>,
			    <0x05e4 0x22988a1b>,
			    <0x05e8 0x309c12ff>,
			    <0x05ec 0x1ed791db>,
			    <0x05f0 0x1ed791db>,
			    <0x05f4 0x1c76f1b1>,
			    <0x05f8 0x16856d4d>,
			    <0x05fc 0x2b9aceac>,
			    <0x0600 0x19b63d82>,
			    <0x0604 0x1ed791db>,
			    <0x0608 0x16856d4d>,
			    <0x060c 0x21b8520d>,
			    <0x0610 0x1825d568>,
			    <0x0614 0x1fe7d9ed>,
			    <0x0618 0x19b63d82>,
			    <0x061c 0x19b63d82>,
			    <0x0620 0x14d4f930>,
			    <0x0624 0x19b63d82>,
			    <0x0628 0x16856d4d>,
			    <0x062c 0x1825d568>,
			    <0x0630 0x16856d4d>,
			    <0x0634 0x16856d4d>,
			    <0x0638 0x1ed791db>,
			    <0x063c 0x14d4f930>,
			    <0x0640 0x1fe7d9ed>,
			    <0x0644 0x16856d4d>,
			    <0x0648 0x21b8520d>,
			    <0x064c 0x19b63d82>,
			    <0x0650 0x20d819fe>,
			    <0x0654 0x19b63d82>,
			    <0x0658 0x1db745c7>,
			    <0x065c 0x16856d4d>,
			    <0x0660 0x1825d568>,
			    <0x0664 0x14d4f930>,
			    <0x0668 0x1ed791db>,
			    <0x066c 0x13048511>,
			    <0x0670 0x16856d4d>,
			    <0x0674 0x2448f636>,
			    <0x0678 0x19b63d82>,
			    <0x067c 0x1fe7d9ed>,
			    <0x0680 0x19b63d82>,
			    <0x0684 0x1db745c7>,
			    <0x0688 0x1825d568>,
			    <0x068c 0x1c76f1b1>,
			    <0x0690 0x14d4f930>,
			    <0x0694 0x19b63d82>,
			    <0x0698 0x08b1ac49>,
			    <0x069c 0x14d4f930>,
			    <0x06a0 0x35fd6f56>,
			    <0x06a4 0x19b63d82>,
			    <0x06a8 0x27a9ce6d>,
			    <0x06ac 0x19b63d82>,
			    <0x06b0 0x19b63d82>,
			    <0x06b4 0x14d4f930>,
			    <0x06b8 0x1db745c7>,
			    <0x06bc 0x16856d4d>,
			    <0x06c0 0x1825d568>,
			    <0x06c4 0x1825d568>,
			    <0x06c8 0x14d4f930>,
			    <0x06cc 0x39ee6795>,
			    <0x06d0 0x1b16999b>,
			    <0x06d4 0x2ddb5ed1>,
			    <0x06d8 0x1c76f1b1>,
			    <0x06dc 0x22988a1b>,
			    <0x06e0 0x19b63d82>,
			    <0x06e4 0x1db745c7>,
			    <0x06e8 0x14d4f930>,
			    <0x06ec 0x1825d568>,
			    <0x06f0 0x14d4f930>,
			    <0x06f4 0x1825d568>,
			    <0x06f8 0x1825d568>,
			    <0x06fc 0x19b63d82>,
			    <0x0700 0x00000000>,
			    <0x0704 0x00000000>,
			    <0x0708 0x00000000>,
			    <0x070c 0x00000000>,
			    <0x0710 0x00000000>,
			    <0x0714 0x00000000>,
			    <0x0718 0x00000000>,
			    <0x071c 0x00000000>,
			    <0x0720 0x00000000>,
			    <0x0724 0x00000000>,
			    <0x0728 0x00000000>,
			    <0x072c 0x00000000>,
			    <0x0730 0x00000000>,
			    <0x0734 0x00000000>,
			    <0x0738 0x00000000>,
			    <0x073c 0x00000000>,
			    <0x0740 0x00000000>,
			    <0x0744 0x00000000>,
			    <0x0748 0x00000000>,
			    <0x074c 0x00000000>,
			    <0x0750 0x00000000>,
			    <0x0754 0x00000000>,
			    <0x0758 0x00000000>,
			    <0x075c 0x00000000>,
			    <0x0760 0x00000000>,
			    <0x0764 0x00000000>,
			    <0x0768 0x00000000>,
			    <0x076c 0x00000000>,
			    <0x0770 0x00000000>,
			    <0x0774 0x00000000>,
			    <0x0778 0x00000000>,
			    <0x077c 0x00000000>,
			    <0x0780 0x00000000>,
			    <0x0784 0x00000000>,
			    <0x0788 0x00000000>,
			    <0x078c 0x00000000>,
			    <0x0790 0x00000000>,
			    <0x0794 0x00000000>,
			    <0x0798 0x00000000>,
			    <0x079c 0x00000000>,
			    <0x07a0 0x00000000>,
			    <0x07a4 0x00000000>,
			    <0x07a8 0x00000000>,
			    <0x07ac 0x00000000>,
			    <0x07b0 0x00000000>,
			    <0x07b4 0x00000000>,
			    <0x07b8 0x00000000>,
			    <0x07bc 0x00000000>,
			    <0x07c0 0x00000000>,
			    <0x07c4 0x00000000>,
			    <0x07c8 0x00000000>,
			    <0x07cc 0x00000000>,
			    <0x07d0 0x00000000>,
			    <0x07d4 0x00000000>,
			    <0x07d8 0x00000000>,
			    <0x07dc 0x00000000>,
			    <0x07e0 0x00000000>,
			    <0x07e4 0x00000000>,
			    <0x07e8 0x00000000>,
			    <0x07ec 0x00000000>,
			    <0x07f0 0x00000000>,
			    <0x07f4 0x00000000>,
			    <0x07f8 0x00000000>,
			    <0x07fc 0x00000000>,
			    <0x0800 0x08b12400>,
			    <0x0804 0x1113c4c6>,
			    <0x0808 0x16853530>,
			    <0x080c 0x1b166d82>,
			    <0x0810 0x1ed76dc7>,
			    <0x0814 0x21b835fe>,
			    <0x0818 0x2448da29>,
			    <0x081c 0x26d97e52>,
			    <0x0820 0x293a1e7a>,
			    <0x0824 0x2b9ab2a0>,
			    <0x0828 0x2ddb46c5>,
			    <0x082c 0x2ffbd2e8>,
			    <0x0830 0x31dc4f09>,
			    <0x0834 0x33acc326>,
			    <0x0838 0x356d3743>,
			    <0x083c 0x372da35f>,
			    <0x0840 0x38ce137b>,
			    <0x0844 0x3a6e7b95>,
			    <0x0848 0x3bfedfaf>,
			    <0x084c 0x3d8f43c8>,
			    <0x0850 0x3effa3e0>,
			    <0x0854 0x000ffff7>,
			    <0x0858 0x00000000>,
			    <0x085c 0x00000000>,
			    <0x0860 0x00000000>,
			    <0x0864 0x00000000>,
			    <0x0868 0x00000000>,
			    <0x086c 0x00000000>,
			    <0x0870 0x00000000>,
			    <0x0874 0x00000000>,
			    <0x0878 0x00000000>,
			    <0x087c 0x00000000>,
			    <0x0880 0x00000000>,
			    <0x0884 0x00000000>,
			    <0x0888 0x00000000>,
			    <0x088c 0x00000000>,
			    <0x0890 0x00000000>,
			    <0x0894 0x00000000>,
			    <0x0898 0x00000000>,
			    <0x089c 0x00000000>,
			    <0x08a0 0x00000000>,
			    <0x08a4 0x00000000>,
			    <0x08a8 0x00000000>,
			    <0x08ac 0x00000000>,
			    <0x08b0 0x00000000>,
			    <0x08b4 0x00000000>,
			    <0x08b8 0x00000000>,
			    <0x08bc 0x00000000>,
			    <0x08c0 0x00000000>,
			    <0x08c4 0x00000000>,
			    <0x08c8 0x00000000>,
			    <0x08cc 0x00000000>,
			    <0x08d0 0x00000000>,
			    <0x08d4 0x00000000>,
			    <0x08d8 0x00000000>,
			    <0x08dc 0x00000000>,
			    <0x08e0 0x00000000>,
			    <0x08e4 0x00000000>,
			    <0x08e8 0x00000000>,
			    <0x08ec 0x00000000>,
			    <0x08f0 0x00000000>,
			    <0x08f4 0x00000000>,
			    <0x08f8 0x00000000>,
			    <0x08fc 0x00000000>;

			  ime_reg_cfg = 
			    <0x0004 0x0a00341e>,
			    <0x0008 0x00000000>,
			    <0x000c 0x80000000>,
			    <0x0010 0x00000000>,
			    <0x0014 0x00000000>,
			    <0x0018 0xa0000040>,
			    <0x001c 0x40000030>,
			    <0x0020 0x04380780>,
			    <0x0024 0x000000f0>,
			    <0x0028 0x001e0000>,
			    <0x002c 0x7f3f0438>,
			    <0x0030 0x00000140>,
			    <0x0034 0x00000140>,
			    <0x0038 0x003c0000>,
			    <0x003c 0x003d2c00>,
			    <0x0040 0x003e5800>,
			    <0x0044 0x00000000>,
			    <0x0048 0x00000000>,
			    <0x004c 0x00000000>,
			    <0x0050 0x00000000>,
			    <0x0054 0x00000000>,
			    <0x0058 0x00000000>,
			    <0x005c 0x00000000>,
			    <0x0060 0x00000012>,
			    <0x0064 0x00000000>,
			    <0x0068 0x00000000>,
			    <0x006c 0x00000000>,
			    <0x0070 0x00000000>,
			    <0x0074 0x00000000>,
			    <0x0078 0x00000000>,
			    <0x007c 0x04380780>,
			    <0x0080 0x00000000>,
			    <0x0084 0x04380780>,
			    <0x0088 0xff00ff00>,
			    <0x008c 0x00000780>,
			    <0x0090 0x00000780>,
			    <0x0094 0x139e7000>,
			    <0x0098 0x13be1400>,
			    <0x009c 0x13be1400>,
			    <0x00a0 0x00000000>,
			    <0x00a4 0x00000000>,
			    <0x00a8 0x00000000>,
			    <0x00ac 0x00000000>,
			    <0x00b0 0x0000001e>,
			    <0x00b4 0x1aef8088>,
			    <0x00b8 0x40ab00cd>,
			    <0x00bc 0x02410301>,
			    <0x00c0 0x071c0555>,
			    <0x00c4 0x07190554>,
			    <0x00c8 0x07160552>,
			    <0x00cc 0x00020400>,
			    <0x00d0 0x00000000>,
			    <0x00d4 0x00000000>,
			    <0x00d8 0x00000000>,
			    <0x00dc 0x00000000>,
			    <0x00e0 0x00000000>,
			    <0x00e4 0x00000000>,
			    <0x00e8 0x00000000>,
			    <0x00ec 0x00000000>,
			    <0x00f0 0x00000000>,
			    <0x00f4 0x00000000>,
			    <0x00f8 0x00000000>,
			    <0x00fc 0x00000000>,
			    <0x0100 0x00000000>,
			    <0x0104 0x01e00280>,
			    <0x0108 0x00000000>,
			    <0x010c 0x01e00280>,
			    <0x0110 0xff00ff00>,
			    <0x0114 0x00000280>,
			    <0x0118 0x00000280>,
			    <0x011c 0x13cdf000>,
			    <0x0120 0x13d2a000>,
			    <0x0124 0x00000000>,
			    <0x0128 0x00000000>,
			    <0x012c 0x00000000>,
			    <0x0130 0x0000001e>,
			    <0x0134 0x11f78184>,
			    <0x0138 0x83bf0044>,
			    <0x013c 0x04840201>,
			    <0x0140 0x038c0800>,
			    <0x0144 0x038b07fc>,
			    <0x0148 0x038a07f8>,
			    <0x014c 0x00040200>,
			    <0x0150 0x00000000>,
			    <0x0154 0x00000000>,
			    <0x0158 0x00000000>,
			    <0x015c 0x00000000>,
			    <0x0160 0x00000000>,
			    <0x0164 0x00000000>,
			    <0x0168 0x00000000>,
			    <0x016c 0x00000000>,
			    <0x0170 0x00000000>,
			    <0x0174 0x00000000>,
			    <0x0178 0x00000000>,
			    <0x017c 0x00000000>,
			    <0x0180 0x00000000>,
			    <0x0184 0x00f003c0>,
			    <0x0188 0x00000000>,
			    <0x018c 0x00f003c0>,
			    <0x0190 0xff00ff00>,
			    <0x0194 0x000003c0>,
			    <0x0198 0x000003c0>,
			    <0x019c 0x142cf000>,
			    <0x01a0 0x14307400>,
			    <0x01a4 0x00000000>,
			    <0x01a8 0x00000000>,
			    <0x01ac 0x00000000>,
			    <0x01b0 0x00000112>,
			    <0x01b4 0x00000000>,
			    <0x01b8 0x00000000>,
			    <0x01bc 0x00000000>,
			    <0x01c0 0x00f00140>,
			    <0x01c4 0x00000000>,
			    <0x01c8 0x00f00140>,
			    <0x01cc 0x0000ff00>,
			    <0x01d0 0x00000050>,
			    <0x01d4 0x00000000>,
			    <0x01d8 0x00499bc0>,
			    <0x01dc 0x00000000>,
			    <0x01e0 0x00000000>,
			    <0x01e4 0x00000000>,
			    <0x01e8 0x00000000>,
			    <0x01ec 0x00000000>,
			    <0x01f0 0x00000000>,
			    <0x01f4 0x00000000>,
			    <0x01f8 0x00000000>,
			    <0x01fc 0x00000000>,
			    <0x0200 0x00000000>,
			    <0x0204 0x00000000>,
			    <0x0208 0x00000000>,
			    <0x020c 0x00000000>,
			    <0x0210 0x00000000>,
			    <0x0214 0x00000000>,
			    <0x0218 0x00000000>,
			    <0x021c 0x00000000>,
			    <0x0220 0x011001e0>,
			    <0x0224 0x404b3fe6>,
			    <0x0228 0x00000140>,
			    <0x022c 0x012b1f00>,
			    <0x0230 0x00000004>,
			    <0x0234 0x00007f80>,
			    <0x0238 0x0002000a>,
			    <0x023c 0x00000bff>,
			    <0x0240 0x0002000a>,
			    <0x0244 0x00200022>,
			    <0x0248 0x0200000a>,
			    <0x024c 0x00000000>,
			    <0x0250 0x8000010c>,
			    <0x0254 0xfb46019a>,
			    <0x0258 0x03fc0402>,
			    <0x025c 0x040503ff>,
			    <0x0260 0x040403fe>,
			    <0x0264 0x040303fd>,
			    <0x0268 0x000005a0>,
			    <0x026c 0x16194a00>,
			    <0x0270 0x00000505>,
			    <0x0274 0x00000000>,
			    <0x0278 0x00000000>,
			    <0x027c 0x00000000>,
			    <0x0280 0x00008080>,
			    <0x0284 0x16c6b9f0>,
			    <0x0288 0x0a63a12a>,
			    <0x028c 0x00008864>,
			    <0x0290 0x16c6b9f0>,
			    <0x0294 0x0a63a12a>,
			    <0x0298 0x00008864>,
			    <0x029c 0x00000000>,
			    <0x02a0 0x00000000>,
			    <0x02a4 0x00000000>,
			    <0x02a8 0x00000000>,
			    <0x02ac 0x00000000>,
			    <0x02b0 0x00000000>,
			    <0x02b4 0x00000000>,
			    <0x02b8 0x00000000>,
			    <0x02bc 0x00000000>,
			    <0x02c0 0x00000000>,
			    <0x02c4 0x00000000>,
			    <0x02c8 0x00000000>,
			    <0x02cc 0x00000000>,
			    <0x02d0 0x00000000>,
			    <0x02d4 0x00000000>,
			    <0x02d8 0x00000000>,
			    <0x02dc 0x00000000>,
			    <0x02e0 0x00000000>,
			    <0x02e4 0x00000000>,
			    <0x02e8 0x00000000>,
			    <0x02ec 0x00000000>,
			    <0x02f0 0x00000000>,
			    <0x02f4 0x00000000>,
			    <0x02f8 0x00000000>,
			    <0x02fc 0x00000000>,
			    <0x0300 0x00000000>,
			    <0x0304 0x00000000>,
			    <0x0308 0x00000000>,
			    <0x030c 0x00000000>,
			    <0x0310 0x00000000>,
			    <0x0314 0x00000000>,
			    <0x0318 0x00000000>,
			    <0x031c 0x00000000>,
			    <0x0320 0x00000000>,
			    <0x0324 0x00000000>,
			    <0x0328 0x00000000>,
			    <0x032c 0x00000000>,
			    <0x0330 0x00000000>,
			    <0x0334 0x00000000>,
			    <0x0338 0x00000000>,
			    <0x033c 0x00000000>,
			    <0x0340 0x00000000>,
			    <0x0344 0x00000000>,
			    <0x0348 0x00000000>,
			    <0x034c 0x00000000>,
			    <0x0350 0x00000000>,
			    <0x0354 0x00000000>,
			    <0x0358 0x00000000>,
			    <0x035c 0x00000000>,
			    <0x0360 0x00000000>,
			    <0x0364 0x00000000>,
			    <0x0368 0x00000000>,
			    <0x036c 0x00000000>,
			    <0x0370 0x00000000>,
			    <0x0374 0x00000000>,
			    <0x0378 0x00000000>,
			    <0x037c 0x00000000>,
			    <0x0380 0x00000000>,
			    <0x0384 0x00000000>,
			    <0x0388 0x00000000>,
			    <0x038c 0x00000000>,
			    <0x0390 0x00000000>,
			    <0x0394 0x00000000>,
			    <0x0398 0x00000000>,
			    <0x039c 0x00000000>,
			    <0x03a0 0x00000000>,
			    <0x03a4 0x00000000>,
			    <0x03a8 0x00000000>,
			    <0x03ac 0x00000000>,
			    <0x03b0 0x00000000>,
			    <0x03b4 0x00000000>,
			    <0x03b8 0x00000000>,
			    <0x03bc 0x00000000>,
			    <0x03c0 0x00000000>,
			    <0x03c4 0x00000000>,
			    <0x03c8 0x00000000>,
			    <0x03cc 0x00000000>,
			    <0x03d0 0x00000000>,
			    <0x03d4 0x00000000>,
			    <0x03d8 0x00000000>,
			    <0x03dc 0x00000000>,
			    <0x03e0 0x00000000>,
			    <0x03e4 0x00000000>,
			    <0x03e8 0x00000000>,
			    <0x03ec 0x00000000>,
			    <0x03f0 0x00000000>,
			    <0x03f4 0x00000000>,
			    <0x03f8 0x00000000>,
			    <0x03fc 0x00000000>,
			    <0x0400 0x00000000>,
			    <0x0404 0x00000000>,
			    <0x0408 0x00000000>,
			    <0x040c 0x00000000>,
			    <0x0410 0x00000000>,
			    <0x0414 0x00000000>,
			    <0x0418 0x00000000>,
			    <0x041c 0x00000000>,
			    <0x0420 0x00000000>,
			    <0x0424 0x00000000>,
			    <0x0428 0x00000000>,
			    <0x042c 0x00000000>,
			    <0x0430 0x00000000>,
			    <0x0434 0x00000000>,
			    <0x0438 0x00000000>,
			    <0x043c 0x00000000>,
			    <0x0440 0x00000000>,
			    <0x0444 0x00000000>,
			    <0x0448 0x00000000>,
			    <0x044c 0x00000000>,
			    <0x0450 0x00000000>,
			    <0x0454 0x00000000>,
			    <0x0458 0x00000000>,
			    <0x045c 0x00000000>,
			    <0x0460 0x00000000>,
			    <0x0464 0x00000000>,
			    <0x0468 0x00000000>,
			    <0x046c 0x00000000>,
			    <0x0470 0x00000000>,
			    <0x0474 0x00000000>,
			    <0x0478 0x00000000>,
			    <0x047c 0x00000000>,
			    <0x0480 0x00000000>,
			    <0x0484 0x00000000>,
			    <0x0488 0x00000000>,
			    <0x048c 0x00000000>,
			    <0x0490 0x00000000>,
			    <0x0494 0x00000000>,
			    <0x0498 0x00000000>,
			    <0x049c 0x00000000>,
			    <0x04a0 0x00000000>,
			    <0x04a4 0x00000000>,
			    <0x04a8 0x00000000>,
			    <0x04ac 0x00000000>,
			    <0x04b0 0x00000000>,
			    <0x04b4 0x00000000>,
			    <0x04b8 0x00000000>,
			    <0x04bc 0x00000000>,
			    <0x04c0 0x00000000>,
			    <0x04c4 0x00000000>,
			    <0x04c8 0x00000000>,
			    <0x04cc 0x00000000>,
			    <0x04d0 0x00000000>,
			    <0x04d4 0x00000000>,
			    <0x04d8 0x00000000>,
			    <0x04dc 0x00000000>,
			    <0x04e0 0x00000000>,
			    <0x04e4 0x00000000>,
			    <0x04e8 0x00000000>,
			    <0x04ec 0x00000000>,
			    <0x04f0 0x00000000>,
			    <0x04f4 0x00000000>,
			    <0x04f8 0x00000000>,
			    <0x04fc 0x00000000>,
			    <0x0500 0x00000000>,
			    <0x0504 0x00000000>,
			    <0x0508 0x00000000>,
			    <0x050c 0x00000000>,
			    <0x0510 0x00000000>,
			    <0x0514 0x00000000>,
			    <0x0518 0x00000000>,
			    <0x051c 0x00000000>,
			    <0x0520 0x00000000>,
			    <0x0524 0x00000000>,
			    <0x0528 0x00000000>,
			    <0x052c 0x00000000>,
			    <0x0530 0x00000000>,
			    <0x0534 0x00000000>,
			    <0x0538 0x00000000>,
			    <0x053c 0x00000000>,
			    <0x0540 0x00000000>,
			    <0x0544 0x00000000>,
			    <0x0548 0x00000000>,
			    <0x054c 0x00000000>,
			    <0x0550 0x00000000>,
			    <0x0554 0x00000000>,
			    <0x0558 0x00000000>,
			    <0x055c 0x00000001>,
			    <0x0560 0x011001e0>,
			    <0x0564 0x00000001>,
			    <0x0568 0x00000000>,
			    <0x056c 0x00000000>,
			    <0x0570 0x01e00fff>,
			    <0x0574 0x00000000>,
			    <0x0578 0x00000000>,
			    <0x057c 0x00000000>,
			    <0x0580 0x00000000>,
			    <0x0584 0x00000000>,
			    <0x0588 0x00000000>,
			    <0x058c 0x00000000>,
			    <0x0590 0x00000000>,
			    <0x0594 0x00000000>,
			    <0x0598 0x00000000>,
			    <0x059c 0x00000000>,
			    <0x05a0 0x0438077f>,
			    <0x05a4 0x01e0027f>,
			    <0x05a8 0x00f003bf>,
			    <0x05ac 0x00000000>,
			    <0x05b0 0x00000000>,
			    <0x05b4 0x04380780>,
			    <0x05b8 0x04380780>,
			    <0x05bc 0x04380780>,
			    <0x05c0 0x00000000>,
			    <0x05c4 0x00000000>,
			    <0x05c8 0x00000000>,
			    <0x05cc 0x00000000>,
			    <0x05d0 0x00000000>,
			    <0x05d4 0x00000000>,
			    <0x05d8 0x00000000>,
			    <0x05dc 0x00000000>,
			    <0x05e0 0x00000000>,
			    <0x05e4 0x00000000>,
			    <0x05e8 0x00000000>,
			    <0x05ec 0x00000000>,
			    <0x05f0 0x00000000>,
			    <0x05f4 0x00000000>,
			    <0x05f8 0x00000000>,
			    <0x05fc 0x00000000>,
			    <0x0600 0x80308f62>,
			    <0x0604 0x00080000>,
			    <0x0608 0x00000000>,
			    <0x060c 0x00000000>,
			    <0x0610 0x00000000>,
			    <0x0614 0x00000000>,
			    <0x0618 0x00000000>,
			    <0x061c 0x0277fe36>,
			    <0x0620 0x0000001c>,
			    <0x0624 0x00000000>,
			    <0x0628 0x0000d836>,
			    <0x062c 0x06c1b06c>,
			    <0x0630 0x00025495>,
			    <0x0634 0x06060606>,
			    <0x0638 0x08070706>,
			    <0x063c 0x00000080>,
			    <0x0640 0x44444344>,
			    <0x0644 0x0010333f>,
			    <0x0648 0x00003fff>,
			    <0x064c 0x00000000>,
			    <0x0650 0x00000000>,
			    <0x0654 0x00000000>,
			    <0x0658 0x00000000>,
			    <0x065c 0x00000000>,
			    <0x0660 0x09080809>,
			    <0x0664 0x07070707>,
			    <0x0668 0x003b0045>,
			    <0x066c 0x003b003b>,
			    <0x0670 0x00310031>,
			    <0x0674 0x00310031>,
			    <0x0678 0x00310032>,
			    <0x067c 0x00340033>,
			    <0x0680 0x003a003a>,
			    <0x0684 0x003b003b>,
			    <0x0688 0x00001008>,
			    <0x068c 0x00000000>,
			    <0x0690 0x00000000>,
			    <0x0694 0x00000000>,
			    <0x0698 0x00000000>,
			    <0x069c 0x00000000>,
			    <0x06a0 0x01900190>,
			    <0x06a4 0x01900190>,
			    <0x06a8 0x051401f4>,
			    <0x06ac 0x05140514>,
			    <0x06b0 0x09080809>,
			    <0x06b4 0x07070707>,
			    <0x06b8 0x003b0045>,
			    <0x06bc 0x003b003b>,
			    <0x06c0 0x00310031>,
			    <0x06c4 0x00310031>,
			    <0x06c8 0x00310032>,
			    <0x06cc 0x00340033>,
			    <0x06d0 0x003a003a>,
			    <0x06d4 0x003b003b>,
			    <0x06d8 0x00001008>,
			    <0x06dc 0x00000000>,
			    <0x06e0 0x00000000>,
			    <0x06e4 0x00000000>,
			    <0x06e8 0x00000000>,
			    <0x06ec 0x00000000>,
			    <0x06f0 0x00001008>,
			    <0x06f4 0x00000000>,
			    <0x06f8 0x00000000>,
			    <0x06fc 0x00000000>,
			    <0x0700 0x00000000>,
			    <0x0704 0x00000000>,
			    <0x0708 0x00000000>,
			    <0x070c 0x00000000>,
			    <0x0710 0x00001008>,
			    <0x0714 0x00000000>,
			    <0x0718 0x00000000>,
			    <0x071c 0x00000000>,
			    <0x0720 0x00000000>,
			    <0x0724 0x00000000>,
			    <0x0728 0x00000000>,
			    <0x072c 0x00000000>,
			    <0x0730 0x3fff0403>,
			    <0x0734 0x0000e6b4>,
			    <0x0738 0x04000200>,
			    <0x073c 0x00640168>,
			    <0x0740 0x00000000>,
			    <0x0744 0x00000000>,
			    <0x0748 0x00000000>,
			    <0x074c 0x00000000>,
			    <0x0750 0x00000000>,
			    <0x0754 0x00000000>,
			    <0x0758 0x00000000>,
			    <0x075c 0x00000000>,
			    <0x0760 0x00ff0603>,
			    <0x0764 0x018000c0>,
			    <0x0768 0x00000000>,
			    <0x076c 0x00000001>,
			    <0x0770 0x20201010>,
			    <0x0774 0x00000000>,
			    <0x0778 0x00000000>,
			    <0x077c 0x00000000>,
			    <0x0780 0x00000000>,
			    <0x0784 0x00000000>,
			    <0x0788 0x00000000>,
			    <0x078c 0x00000000>,
			    <0x0790 0x10101010>,
			    <0x0794 0x10101010>,
			    <0x0798 0x00000000>,
			    <0x079c 0x00000000>,
			    <0x07a0 0x00000000>,
			    <0x07a4 0x00000000>,
			    <0x07a8 0x00000000>,
			    <0x07ac 0x00000000>,
			    <0x07b0 0x20100804>,
			    <0x07b4 0x00000000>,
			    <0x07b8 0x00000000>,
			    <0x07bc 0x00000000>,
			    <0x07c0 0x14004080>,
			    <0x07c4 0x00209632>,
			    <0x07c8 0x01f401f4>,
			    <0x07cc 0x1c181008>,
			    <0x07d0 0x1b130b00>,
			    <0x07d4 0x3a312b23>,
			    <0x07d8 0x1e150d00>,
			    <0x07dc 0x3c312923>,
			    <0x07e0 0x00004080>,
			    <0x07e4 0x00000000>,
			    <0x07e8 0x00000000>,
			    <0x07ec 0x00000000>,
			    <0x07f0 0x00000000>,
			    <0x07f4 0x00000000>,
			    <0x07f8 0x00000000>,
			    <0x07fc 0x00000000>,
			    <0x0800 0x00000780>,
			    <0x0804 0x00000780>,
			    <0x0808 0x13fd7000>,
			    <0x080c 0x141d1400>,
			    <0x0810 0x00000000>,
			    <0x0814 0x00000000>,
			    <0x0818 0x00000000>,
			    <0x081c 0x00000000>,
			    <0x0820 0x00000010>,
			    <0x0824 0x16233500>,
			    <0x0828 0x00000000>,
			    <0x082c 0x16233940>,
			    <0x0830 0x00000010>,
			    <0x0834 0x162341c0>,
			    <0x0838 0x000001e0>,
			    <0x083c 0x161f4400>,
			    <0x0840 0x00000000>,
			    <0x0844 0x16213c80>,
			    <0x0848 0x00000000>,
			    <0x084c 0x00000000>,
			    <0x0850 0x00000000>,
			    <0x0854 0x00000000>,
			    <0x0858 0x00000000>,
			    <0x085c 0x00000000>,
			    <0x0860 0x00000000>,
			    <0x0864 0x00000000>,
			    <0x0868 0x00000000>,
			    <0x086c 0x00000000>,
			    <0x0870 0x00000000>,
			    <0x0874 0x00000000>,
			    <0x0878 0x00000000>,
			    <0x087c 0x00000000>,
			    <0x0880 0x00000000>,
			    <0x0884 0x00000000>,
			    <0x0888 0x00000000>,
			    <0x088c 0x00000000>,
			    <0x0890 0x00000000>,
			    <0x0894 0x00000000>,
			    <0x0898 0x00000000>,
			    <0x089c 0x00000000>,
			    <0x08a0 0x00000000>,
			    <0x08a4 0x00000000>,
			    <0x08a8 0x00000000>,
			    <0x08ac 0x00000000>,
			    <0x08b0 0x00000000>,
			    <0x08b4 0x00000000>,
			    <0x08b8 0x00000000>,
			    <0x08bc 0x00000000>,
			    <0x08c0 0x00000000>,
			    <0x08c4 0x00000000>,
			    <0x08c8 0x00000000>,
			    <0x08cc 0x00000000>,
			    <0x08d0 0x00000000>,
			    <0x08d4 0x00000000>,
			    <0x08d8 0x00000000>,
			    <0x08dc 0x00000000>,
			    <0x08e0 0x00000000>,
			    <0x08e4 0x00000000>,
			    <0x08e8 0x00000000>,
			    <0x08ec 0x00000000>,
			    <0x08f0 0x00000000>,
			    <0x08f4 0x00000000>,
			    <0x08f8 0x00000000>,
			    <0x08fc 0x00000000>,
			    <0x0900 0x00000000>,
			    <0x0904 0x00000000>,
			    <0x0908 0x00000000>,
			    <0x090c 0x00000000>,
			    <0x0910 0x0bb41249>,
			    <0x0914 0x00000748>,
			    <0x0918 0x08e80e39>,
			    <0x091c 0x000005a6>,
			    <0x0920 0x08080ccd>,
			    <0x0924 0x0000051f>,
			    <0x0928 0x07500ba3>,
			    <0x092c 0x000004ae>,
			    <0x0930 0x063509d9>,
			    <0x0934 0x000003f3>,
			    <0x0938 0x05c50925>,
			    <0x093c 0x000003a4>,
			    <0x0940 0x050f0800>,
			    <0x0944 0x00000336>,
			    <0x0948 0x0480071c>,
			    <0x094c 0x000002d9>,
			    <0x0950 0x040e0666>,
			    <0x0954 0x0000028f>,
			    <0x0958 0x03b105d1>,
			    <0x095c 0x00000253>,
			    <0x0960 0x031a04ec>,
			    <0x0964 0x000001f9>,
			    <0x0968 0x02e20492>,
			    <0x096c 0x000001d5>,
			    <0x0970 0x02870400>,
			    <0x0974 0x00000199>,
			    <0x0978 0x0240038e>,
			    <0x097c 0x0000016d>,
			    <0x0980 0x02070333>,
			    <0x0984 0x00000148>,
			    <0x0988 0x01730249>,
			    <0x098c 0x000000ea>,
			    <0x0990 0x00e30124>,
			    <0x0994 0x00ba00cc>,
			    <0x0998 0x0092009d>,
			    <0x099c 0x00720080>,
			    <0x09a0 0x005d0066>,
			    <0x09a4 0x0049004f>,
			    <0x09a8 0x00390040>,
			    <0x09ac 0x00250033>,
			    <0x09b0 0x00000000>,
			    <0x09b4 0x00000000>,
			    <0x09b8 0x00000000>,
			    <0x09bc 0x00000000>,
			    <0x09c0 0x0023001c>,
			    <0x09c4 0x0000002d>,
			    <0x09c8 0x002e0024>,
			    <0x09cc 0x0000003a>,
			    <0x09d0 0x00330028>,
			    <0x09d4 0x00000040>,
			    <0x09d8 0x0038002c>,
			    <0x09dc 0x00000046>,
			    <0x09e0 0x00420034>,
			    <0x09e4 0x00000053>,
			    <0x09e8 0x00470038>,
			    <0x09ec 0x0000005a>,
			    <0x09f0 0x00510040>,
			    <0x09f4 0x00000066>,
			    <0x09f8 0x005b0048>,
			    <0x09fc 0x00000073>,
			    <0x0a00 0x00650050>,
			    <0x0a04 0x00000080>,
			    <0x0a08 0x006f0058>,
			    <0x0a0c 0x0000008d>,
			    <0x0a10 0x00840068>,
			    <0x0a14 0x000000a6>,
			    <0x0a18 0x008e0070>,
			    <0x0a1c 0x000000b3>,
			    <0x0a20 0x00a20080>,
			    <0x0a24 0x000000cd>,
			    <0x0a28 0x00b60090>,
			    <0x0a2c 0x000000e6>,
			    <0x0a30 0x00ca00a0>,
			    <0x0a34 0x00000100>,
			    <0x0a38 0x011b00e0>,
			    <0x0a3c 0x00000166>;

			  ife2_reg_cfg = 
			    <0x0004 0x00030050>,
			    <0x0008 0x80000000>,
			    <0x000c 0x00000000>,
			    <0x0010 0x00000000>,
			    <0x0014 0x011001e0>,
			    <0x0018 0x80000000>,
			    <0x001c 0x000005a0>,
			    <0x0020 0x16135000>,
			    <0x0024 0x00000000>,
			    <0x0028 0x00000000>,
			    <0x002c 0x003c0000>,
			    <0x0030 0x00000280>,
			    <0x0034 0x00141000>,
			    <0x0038 0x00000000>,
			    <0x003c 0x00000000>,
			    <0x0040 0x00000000>,
			    <0x0044 0x100d0b08>,
			    <0x0048 0x00051248>,
			    <0x004c 0x100d0b08>,
			    <0x0050 0x00051248>,
			    <0x0054 0x00090909>,
			    <0x0058 0x00002020>,
			    <0x005c 0x100d0b08>,
			    <0x0060 0x00000016>,
			    <0x0064 0x00111110>,
			    <0x0068 0x100d0b08>,
			    <0x006c 0x00000016>,
			    <0x0070 0x00111110>,
			    <0x0074 0x100d0b08>,
			    <0x0078 0x00000016>,
			    <0x007c 0x00111110>,
			    <0x0080 0x0000837d>,
			    <0x0084 0x00059785>,
			    <0x0088 0x00000008>,
			    <0x008c 0x0000837d>,
			    <0x0090 0x0004ac0a>,
			    <0x0094 0x00000008>,
			    <0x0098 0x00008abe>,
			    <0x009c 0x00000000>,
			    <0x00a0 0x00000000>,
			    <0x00a4 0x00000000>,
			    <0x00a8 0x00000000>,
			    <0x00ac 0x00000000>;

			};
		};
		config-1 {
			hdl_name = "vdoprc1";
			flow = <1>;
			isp_id = <0x1>;
			func_en = <0x6bd>;
			3dnr_ref_path = <0x0>;
			buffer_func_en = <0x6bd>;
			buffer-size {
				lca = <0x5fa00>;
				3dnr_mv = <0x1f880>;
				3dnr_ms = <0x440>;
				3dnr_ms_roi = <0x440>;
				3dnr_sta = <0xa000>;
				defog = <0x1000>;
				pm = <0x0>;
				wdr = <0x2000>;
				va = <0x0>;
				dummy_uv = <0x0>;
			};
			frm-rate-ctrl {
				skip = <0 0 0 0 0 0>;
				src = <30 30 30 30 30 30>;
				dst = <30 30 30 30 30 30>;
			};
			register {
			  ife_reg_num = <469>;
			  dce_reg_num = <393>;
			  ipe_reg_num = <575>;
			  ime_reg_num = <655>;
			  ife2_reg_num = <43>;

			  ife_reg_cfg = 
			    <0x0004 0x00c3e141>,
			    <0x0008 0x000013ff>,
			    <0x000c 0x00006800>,
			    <0x0010 0xffc00003>,
			    <0x0014 0x00000000>,
			    <0x0018 0x1fff0000>,
			    <0x001c 0x00000000>,
			    <0x0020 0x04380780>,
			    <0x0024 0x04380780>,
			    <0x0028 0x00000000>,
			    <0x002c 0x00000000>,
			    <0x0030 0x130f90c0>,
			    <0x0034 0x00000b40>,
			    <0x0038 0x00800000>,
			    <0x003c 0x00000000>,
			    <0x0040 0x00000000>,
			    <0x0044 0x00000000>,
			    <0x0048 0x00000000>,
			    <0x004c 0x00000000>,
			    <0x0050 0x00000000>,
			    <0x0054 0x00800000>,
			    <0x0058 0x00000000>,
			    <0x005c 0x00001000>,
			    <0x0060 0x00000000>,
			    <0x0064 0x00000000>,
			    <0x0068 0x00000000>,
			    <0x006c 0x00000000>,
			    <0x0070 0x000fff08>,
			    <0x0074 0x011201ee>,
			    <0x0078 0x02830112>,
			    <0x007c 0x00000112>,
			    <0x0080 0x00800080>,
			    <0x0084 0x00800080>,
			    <0x0088 0x00000080>,
			    <0x008c 0x00800080>,
			    <0x0090 0x00800080>,
			    <0x0094 0x00000080>,
			    <0x0098 0x00000000>,
			    <0x009c 0x00000000>,
			    <0x00a0 0x00000000>,
			    <0x00a4 0x00000000>,
			    <0x00a8 0x00000000>,
			    <0x00ac 0x00000000>,
			    <0x00b0 0x01000100>,
			    <0x00b4 0x01000100>,
			    <0x00b8 0x00000100>,
			    <0x00bc 0x00000000>,
			    <0x00c0 0x00000000>,
			    <0x00c4 0x00000000>,
			    <0x00c8 0x00000000>,
			    <0x00cc 0x00000000>,
			    <0x00d0 0x00000000>,
			    <0x00d4 0x00000000>,
			    <0x00d8 0x00000000>,
			    <0x00dc 0x00000000>,
			    <0x00e0 0x00000000>,
			    <0x00e4 0x00000000>,
			    <0x00e8 0x00000000>,
			    <0x00ec 0x00000000>,
			    <0x00f0 0x00000000>,
			    <0x00f4 0x00000000>,
			    <0x00f8 0x00000000>,
			    <0x00fc 0x00000000>,
			    <0x0100 0x00080040>,
			    <0x0104 0x00501200>,
			    <0x0108 0x0911171f>,
			    <0x010c 0x00000307>,
			    <0x0110 0x00010000>,
			    <0x0114 0x00020001>,
			    <0x0118 0x00030002>,
			    <0x011c 0x00000000>,
			    <0x0120 0x00010000>,
			    <0x0124 0x00020001>,
			    <0x0128 0x00030002>,
			    <0x012c 0x00000000>,
			    <0x0130 0x00010000>,
			    <0x0134 0x00020001>,
			    <0x0138 0x00030002>,
			    <0x013c 0x00000000>,
			    <0x0140 0x00010000>,
			    <0x0144 0x00020001>,
			    <0x0148 0x00030002>,
			    <0x014c 0x00000000>,
			    <0x0150 0x00020000>,
			    <0x0154 0x00040002>,
			    <0x0158 0x00060004>,
			    <0x015c 0x00000000>,
			    <0x0160 0x00020000>,
			    <0x0164 0x00040002>,
			    <0x0168 0x00060004>,
			    <0x016c 0x00000000>,
			    <0x0170 0x00020000>,
			    <0x0174 0x00040002>,
			    <0x0178 0x00060004>,
			    <0x017c 0x00000000>,
			    <0x0180 0x00020000>,
			    <0x0184 0x00040002>,
			    <0x0188 0x00060004>,
			    <0x018c 0x00000000>,
			    <0x0190 0x002c62c6>,
			    <0x0194 0x0040c40c>,
			    <0x0198 0x006af6af>,
			    <0x019c 0x0093d93d>,
			    <0x01a0 0x00f41f41>,
			    <0x01a4 0x00010000>,
			    <0x01a8 0x00010033>,
			    <0x01ac 0x86543210>,
			    <0x01b0 0x86543210>,
			    <0x01b4 0x00f00001>,
			    <0x01b8 0x008000a0>,
			    <0x01bc 0x000010ff>,
			    <0x01c0 0x00020000>,
			    <0x01c4 0x00030002>,
			    <0x01c8 0x00040004>,
			    <0x01cc 0x00050004>,
			    <0x01d0 0x00060005>,
			    <0x01d4 0x00060006>,
			    <0x01d8 0x00070006>,
			    <0x01dc 0x00070007>,
			    <0x01e0 0x00000008>,
			    <0x01e4 0x00020000>,
			    <0x01e8 0x00030002>,
			    <0x01ec 0x00040004>,
			    <0x01f0 0x00050004>,
			    <0x01f4 0x00060005>,
			    <0x01f8 0x00060006>,
			    <0x01fc 0x00070006>,
			    <0x0200 0x00070007>,
			    <0x0204 0x00000008>,
			    <0x0208 0x00020000>,
			    <0x020c 0x00030002>,
			    <0x0210 0x00040004>,
			    <0x0214 0x00050004>,
			    <0x0218 0x00060005>,
			    <0x021c 0x00060006>,
			    <0x0220 0x00070006>,
			    <0x0224 0x00070007>,
			    <0x0228 0x00000008>,
			    <0x022c 0x00020000>,
			    <0x0230 0x00030002>,
			    <0x0234 0x00040004>,
			    <0x0238 0x00050004>,
			    <0x023c 0x00060005>,
			    <0x0240 0x00060006>,
			    <0x0244 0x00070006>,
			    <0x0248 0x00070007>,
			    <0x024c 0x00000008>,
			    <0x0250 0x00040000>,
			    <0x0254 0x00060004>,
			    <0x0258 0x00080008>,
			    <0x025c 0x000a0008>,
			    <0x0260 0x000c000a>,
			    <0x0264 0x000c000c>,
			    <0x0268 0x000e000c>,
			    <0x026c 0x000e000e>,
			    <0x0270 0x00000010>,
			    <0x0274 0x00040000>,
			    <0x0278 0x00060004>,
			    <0x027c 0x00080008>,
			    <0x0280 0x000a0008>,
			    <0x0284 0x000c000a>,
			    <0x0288 0x000c000c>,
			    <0x028c 0x000e000c>,
			    <0x0290 0x000e000e>,
			    <0x0294 0x00000010>,
			    <0x0298 0x00040000>,
			    <0x029c 0x00060004>,
			    <0x02a0 0x00080008>,
			    <0x02a4 0x000a0008>,
			    <0x02a8 0x000c000a>,
			    <0x02ac 0x000c000c>,
			    <0x02b0 0x000e000c>,
			    <0x02b4 0x000e000e>,
			    <0x02b8 0x00000010>,
			    <0x02bc 0x00040000>,
			    <0x02c0 0x00060004>,
			    <0x02c4 0x00080008>,
			    <0x02c8 0x000a0008>,
			    <0x02cc 0x000c000a>,
			    <0x02d0 0x000c000c>,
			    <0x02d4 0x000e000c>,
			    <0x02d8 0x000e000e>,
			    <0x02dc 0x00000010>,
			    <0x02e0 0x021c03c0>,
			    <0x02e4 0x021c03c0>,
			    <0x02e8 0x021c03c0>,
			    <0x02ec 0x021c03c0>,
			    <0x02f0 0x003b73b8>,
			    <0x02f4 0x00000001>,
			    <0x02f8 0x00000000>,
			    <0x02fc 0x00000000>,
			    <0x0300 0x00000000>,
			    <0x0304 0x00000000>,
			    <0x0308 0x00000000>,
			    <0x030c 0x00000000>,
			    <0x0310 0x00000000>,
			    <0x0314 0x00000000>,
			    <0x0318 0x00000000>,
			    <0x031c 0x00000000>,
			    <0x0320 0x00000000>,
			    <0x0324 0x00000000>,
			    <0x0328 0x00000000>,
			    <0x032c 0x00000000>,
			    <0x0330 0x00000000>,
			    <0x0334 0x00000000>,
			    <0x0338 0x00000000>,
			    <0x033c 0x00000000>,
			    <0x0340 0x00000000>,
			    <0x0344 0x00000000>,
			    <0x0348 0x00000000>,
			    <0x034c 0x00000000>,
			    <0x0350 0x00000000>,
			    <0x0354 0x00000000>,
			    <0x0358 0x00000000>,
			    <0x035c 0x00000000>,
			    <0x0360 0x00000000>,
			    <0x0364 0x00000000>,
			    <0x0368 0x00000000>,
			    <0x036c 0x00000000>,
			    <0x0370 0x00000000>,
			    <0x0374 0x00000000>,
			    <0x0378 0x00000000>,
			    <0x037c 0x00000000>,
			    <0x0380 0x00000000>,
			    <0x0384 0x00000000>,
			    <0x0388 0x09060301>,
			    <0x038c 0x15120f0d>,
			    <0x0390 0x211e1b18>,
			    <0x0394 0x2d2a2724>,
			    <0x0398 0x00000030>,
			    <0x039c 0x1b181000>,
			    <0x03a0 0x1f1e1c1b>,
			    <0x03a4 0x1c1d1e1f>,
			    <0x03a8 0x0c1a1b1c>,
			    <0x03ac 0x00000004>,
			    <0x03b0 0x00000000>,
			    <0x03b4 0x00000000>,
			    <0x03b8 0x00000000>,
			    <0x03bc 0x00000000>,
			    <0x03c0 0x1f1f1f1f>,
			    <0x03c4 0x1e1e1f1f>,
			    <0x03c8 0x14181c1d>,
			    <0x03cc 0x080a0c10>,
			    <0x03d0 0x06060606>,
			    <0x03d4 0x05050505>,
			    <0x03d8 0x04040404>,
			    <0x03dc 0x20010203>,
			    <0x03e0 0x00000000>,
			    <0x03e4 0x00000000>,
			    <0x03e8 0x00000000>,
			    <0x03ec 0x00000000>,
			    <0x03f0 0x00000000>,
			    <0x03f4 0x00000000>,
			    <0x03f8 0x00000000>,
			    <0x03fc 0x00000000>,
			    <0x0400 0x00000000>,
			    <0x0404 0x00000000>,
			    <0x0408 0x00000000>,
			    <0x040c 0x01000000>,
			    <0x0410 0x00000000>,
			    <0x0414 0x00000000>,
			    <0x0418 0x00000000>,
			    <0x041c 0x01000000>,
			    <0x0420 0x00000000>,
			    <0x0424 0x00000000>,
			    <0x0428 0x00000000>,
			    <0x042c 0x00000000>,
			    <0x0430 0x00000000>,
			    <0x0434 0x00000000>,
			    <0x0438 0x00000000>,
			    <0x043c 0x00000000>,
			    <0x0440 0x00000000>,
			    <0x0444 0x00000000>,
			    <0x0448 0x00000000>,
			    <0x044c 0x00000000>,
			    <0x0450 0x00000000>,
			    <0x0454 0x00000000>,
			    <0x0458 0x00000000>,
			    <0x045c 0x00000000>,
			    <0x0460 0x00000000>,
			    <0x0464 0x00000000>,
			    <0x0468 0x00000000>,
			    <0x046c 0x00000000>,
			    <0x0470 0x00000000>,
			    <0x0474 0x00000000>,
			    <0x0478 0x00000000>,
			    <0x047c 0x00000000>,
			    <0x0480 0x00000000>,
			    <0x0484 0x00000000>,
			    <0x0488 0x00000000>,
			    <0x048c 0x00000000>,
			    <0x0490 0x00000000>,
			    <0x0494 0x00000000>,
			    <0x0498 0x00000000>,
			    <0x049c 0x00000000>,
			    <0x04a0 0x00000000>,
			    <0x04a4 0x00000000>,
			    <0x04a8 0x00000000>,
			    <0x04ac 0x00000000>,
			    <0x04b0 0x00000000>,
			    <0x04b4 0x00000000>,
			    <0x04b8 0x00000000>,
			    <0x04bc 0x00000000>,
			    <0x04c0 0x00000000>,
			    <0x04c4 0x00000000>,
			    <0x04c8 0x00000000>,
			    <0x04cc 0x00000000>,
			    <0x04d0 0x00000000>,
			    <0x04d4 0x00000000>,
			    <0x04d8 0x00000000>,
			    <0x04dc 0x00000000>,
			    <0x04e0 0x00000000>,
			    <0x04e4 0x00000000>,
			    <0x04e8 0x00000000>,
			    <0x04ec 0x00000000>,
			    <0x04f0 0x00000000>,
			    <0x04f4 0x00000000>,
			    <0x04f8 0x00000000>,
			    <0x04fc 0x00000000>,
			    <0x0500 0x00000000>,
			    <0x0504 0x00000000>,
			    <0x0508 0x00000000>,
			    <0x050c 0x00000000>,
			    <0x0510 0x00000000>,
			    <0x0514 0x00000000>,
			    <0x0518 0x00000000>,
			    <0x051c 0x00000000>,
			    <0x0520 0x00000000>,
			    <0x0524 0x00000000>,
			    <0x0528 0x00000000>,
			    <0x052c 0x00000000>,
			    <0x0530 0x00000000>,
			    <0x0534 0x00000000>,
			    <0x0538 0x00000000>,
			    <0x053c 0x00000000>,
			    <0x0540 0x00000000>,
			    <0x0544 0x00000000>,
			    <0x0548 0x00000000>,
			    <0x054c 0x00000000>,
			    <0x0550 0x00100210>,
			    <0x0554 0x0e009c00>,
			    <0x0558 0x810060c0>,
			    <0x055c 0x0e009c00>,
			    <0x0560 0x810060c0>,
			    <0x0564 0x00000000>,
			    <0x0568 0x00000000>,
			    <0x056c 0x00000000>,
			    <0x0570 0x00000100>,
			    <0x0574 0x18a41040>,
			    <0x0578 0x10a63a0e>,
			    <0x057c 0x00000886>,
			    <0x0580 0x18a41040>,
			    <0x0584 0x10a63a0e>,
			    <0x0588 0x00000886>,
			    <0x058c 0x00000000>,
			    <0x0590 0xff100fff>,
			    <0x0594 0xff100fff>,
			    <0x0598 0x00000000>,
			    <0x059c 0x00000000>,
			    <0x05a0 0x00400010>,
			    <0x05a4 0x00000100>,
			    <0x05a8 0x00400000>,
			    <0x05ac 0x04000100>,
			    <0x05b0 0x00002222>,
			    <0x05b4 0x00000000>,
			    <0x05b8 0x00000000>,
			    <0x05bc 0x00000000>,
			    <0x05c0 0x00000000>,
			    <0x05c4 0x00000000>,
			    <0x05c8 0x00000000>,
			    <0x05cc 0x00000000>,
			    <0x05d0 0x00000000>,
			    <0x05d4 0x00000000>,
			    <0x05d8 0x00000000>,
			    <0x05dc 0x00000000>,
			    <0x05e0 0x00000000>,
			    <0x05e4 0x00000000>,
			    <0x05e8 0x00000000>,
			    <0x05ec 0x00000000>,
			    <0x05f0 0x00000000>,
			    <0x05f4 0x00000000>,
			    <0x05f8 0x00000000>,
			    <0x05fc 0x00000000>,
			    <0x0600 0x00000004>,
			    <0x0604 0xffffffff>,
			    <0x0608 0x80a0c0e0>,
			    <0x060c 0x10204060>,
			    <0x0610 0x00000000>,
			    <0x0614 0x00000000>,
			    <0x0618 0x06040200>,
			    <0x061c 0x0e0c0a08>,
			    <0x0620 0x16141210>,
			    <0x0624 0x1e1c1a18>,
			    <0x0628 0x26242220>,
			    <0x062c 0x2e2c2a28>,
			    <0x0630 0x36343230>,
			    <0x0634 0x3e3c3a38>,
			    <0x0638 0x55555555>,
			    <0x063c 0x55555555>,
			    <0x0640 0x03430000>,
			    <0x0644 0x060604e9>,
			    <0x0648 0x078b06de>,
			    <0x064c 0x0898081c>,
			    <0x0650 0x09670905>,
			    <0x0654 0x0a0e09be>,
			    <0x0658 0x0a9b0a57>,
			    <0x065c 0x0b140ad9>,
			    <0x0660 0x0b7f0b4b>,
			    <0x0664 0x0bde0bb0>,
			    <0x0668 0x0c340c0a>,
			    <0x066c 0x0c830c5c>,
			    <0x0670 0x0ccb0ca8>,
			    <0x0674 0x0d0d0ced>,
			    <0x0678 0x0d4b0d2d>,
			    <0x067c 0x0d850d69>,
			    <0x0680 0x0dbc0da1>,
			    <0x0684 0x0def0dd6>,
			    <0x0688 0x0e200e08>,
			    <0x068c 0x0e4e0e37>,
			    <0x0690 0x0e790e64>,
			    <0x0694 0x0ea30e8e>,
			    <0x0698 0x0ecb0eb7>,
			    <0x069c 0x0ef10ede>,
			    <0x06a0 0x0f150f03>,
			    <0x06a4 0x0f380f27>,
			    <0x06a8 0x0f5a0f49>,
			    <0x06ac 0x0f7a0f6a>,
			    <0x06b0 0x0f9a0f8a>,
			    <0x06b4 0x0fb80fa9>,
			    <0x06b8 0x0fd50fc7>,
			    <0x06bc 0x0ff20fe4>,
			    <0x06c0 0x00000fff>,
			    <0x06c4 0x00000000>,
			    <0x06c8 0x00000000>,
			    <0x06cc 0x00000000>,
			    <0x06d0 0x00000000>,
			    <0x06d4 0x00000000>,
			    <0x06d8 0x00000000>,
			    <0x06dc 0x00000000>,
			    <0x06e0 0x00000000>,
			    <0x06e4 0x00000000>,
			    <0x06e8 0x00000000>,
			    <0x06ec 0x00000000>,
			    <0x06f0 0x00000000>,
			    <0x06f4 0x00000000>,
			    <0x06f8 0x00000000>,
			    <0x06fc 0x00000000>,
			    <0x0700 0x00000011>,
			    <0x0704 0x0c080400>,
			    <0x0708 0x1c181410>,
			    <0x070c 0x0002aaaa>,
			    <0x0710 0x0002aaaa>,
			    <0x0714 0x00200000>,
			    <0x0718 0x00600040>,
			    <0x071c 0x00a00080>,
			    <0x0720 0x00e000c0>,
			    <0x0724 0x01440100>,
			    <0x0728 0x01e40190>,
			    <0x072c 0x02a40240>,
			    <0x0730 0x03840310>,
			    <0x0734 0x04840400>,
			    <0x0738 0x05a40510>,
			    <0x073c 0x06e40640>,
			    <0x0740 0x08440790>,
			    <0x0744 0x09c40900>,
			    <0x0748 0x0b640a90>,
			    <0x074c 0x0d240c40>,
			    <0x0750 0x0f040e10>,
			    <0x0754 0x00000fff>;

			  dce_reg_cfg = 
			    <0x0004 0x00004614>,
			    <0x0008 0x00001fdf>,
			    <0x000c 0x00000000>,
			    <0x0010 0x04380780>,
			    <0x0014 0x00000000>,
			    <0x0018 0x00000010>,
			    <0x001c 0x00400000>,
			    <0x0020 0x00400000>,
			    <0x0024 0x00000780>,
			    <0x0028 0x00400000>,
			    <0x002c 0x00000780>,
			    <0x0030 0x00400000>,
			    <0x0034 0x00000780>,
			    <0x0038 0x00400000>,
			    <0x003c 0x00000780>,
			    <0x0040 0x00000021>,
			    <0x0044 0x11244912>,
			    <0x0048 0x11244912>,
			    <0x004c 0x0f23c912>,
			    <0x0050 0x0f23c8f2>,
			    <0x0054 0x0f23c8f2>,
			    <0x0058 0x000000f2>,
			    <0x005c 0x7f340000>,
			    <0x0060 0x00000000>,
			    <0x0064 0x044f0000>,
			    <0x0068 0x044f0000>,
			    <0x006c 0x00000012>,
			    <0x0070 0x00000000>,
			    <0x0074 0x00000000>,
			    <0x0078 0x00000000>,
			    <0x007c 0x00000000>,
			    <0x0080 0x00000000>,
			    <0x0084 0x00000000>,
			    <0x0088 0x00000000>,
			    <0x008c 0x00000780>,
			    <0x0090 0x00000000>,
			    <0x0094 0x00000000>,
			    <0x0098 0x00000000>,
			    <0x009c 0x00000000>,
			    <0x00a0 0x00000000>,
			    <0x00a4 0x00400000>,
			    <0x00a8 0x2c0003c0>,
			    <0x00ac 0x000a0028>,
			    <0x00b0 0x80000000>,
			    <0x00b4 0x00000000>,
			    <0x00b8 0xf8888888>,
			    <0x00bc 0x485f7880>,
			    <0x00c0 0x2428303a>,
			    <0x00c4 0x20202020>,
			    <0x00c8 0x20202020>,
			    <0x00cc 0x00a00020>,
			    <0x00d0 0x00014008>,
			    <0x00d4 0x122347ff>,
			    <0x00d8 0x00000111>,
			    <0x00dc 0x00000000>,
			    <0x00e0 0x40081007>,
			    <0x00e4 0x00408003>,
			    <0x00e8 0x00cc00cc>,
			    <0x00ec 0xa80080e6>,
			    <0x00f0 0x00800080>,
			    <0x00f4 0x00010080>,
			    <0x00f8 0x00000100>,
			    <0x00fc 0xffffe0c0>,
			    <0x0100 0x00000000>,
			    <0x0104 0x00000000>,
			    <0x0108 0x00000000>,
			    <0x010c 0x00000000>,
			    <0x0110 0x00000000>,
			    <0x0114 0x00000000>,
			    <0x0118 0x00000000>,
			    <0x011c 0x00000000>,
			    <0x0120 0x0000023f>,
			    <0x0124 0x16353600>,
			    <0x0128 0x00000100>,
			    <0x012c 0x16355600>,
			    <0x0130 0x00000100>,
			    <0x0134 0x04080422>,
			    <0x0138 0x0f79cc3b>,
			    <0x013c 0x0fde1c3b>,
			    <0x0140 0x00000000>,
			    <0x0144 0x00000000>,
			    <0x0148 0x00000000>,
			    <0x014c 0x00000000>,
			    <0x0150 0x00000000>,
			    <0x0154 0x20000000>,
			    <0x0158 0x00000054>,
			    <0x015c 0x1565193c>,
			    <0x0160 0x160c160c>,
			    <0x0164 0x05030003>,
			    <0x0168 0x00000000>,
			    <0x016c 0x00000000>,
			    <0x0170 0x00000000>,
			    <0x0174 0x00000000>,
			    <0x0178 0x00000000>,
			    <0x017c 0x00000000>,
			    <0x0180 0x00000000>,
			    <0x0184 0x00000000>,
			    <0x0188 0x00000000>,
			    <0x018c 0x00000000>,
			    <0x0190 0x00000000>,
			    <0x0194 0x00000000>,
			    <0x0198 0x00000000>,
			    <0x019c 0x00000000>,
			    <0x01a0 0x00000000>,
			    <0x01a4 0x00000000>,
			    <0x01a8 0x00000000>,
			    <0x01ac 0x00000000>,
			    <0x01b0 0x00000000>,
			    <0x01b4 0x00000000>,
			    <0x01b8 0x00000000>,
			    <0x01bc 0x00000000>,
			    <0x01c0 0x00000000>,
			    <0x01c4 0x00000000>,
			    <0x01c8 0x00000000>,
			    <0x01cc 0x00000000>,
			    <0x01d0 0x00000000>,
			    <0x01d4 0x00000000>,
			    <0x01d8 0x00000000>,
			    <0x01dc 0x00000000>,
			    <0x01e0 0x00000000>,
			    <0x01e4 0x00000000>,
			    <0x01e8 0x00000000>,
			    <0x01ec 0x00000000>,
			    <0x01f0 0x00000000>,
			    <0x01f4 0x00000000>,
			    <0x01f8 0x00000000>,
			    <0x01fc 0x00000000>,
			    <0x0200 0x00000000>,
			    <0x0204 0x00000000>,
			    <0x0208 0x00000000>,
			    <0x020c 0x00000000>,
			    <0x0210 0x00000000>,
			    <0x0214 0x18100800>,
			    <0x0218 0x2624201c>,
			    <0x021c 0x2b2a2928>,
			    <0x0220 0x2f2e2d2c>,
			    <0x0224 0x33323130>,
			    <0x0228 0x37363534>,
			    <0x022c 0x3b3a3938>,
			    <0x0230 0x3f3e3d3c>,
			    <0x0234 0x00005abf>,
			    <0x0238 0x00000000>,
			    <0x023c 0x0ff70fff>,
			    <0x0240 0x0fa10fd8>,
			    <0x0244 0x0ef10f54>,
			    <0x0248 0x0df70e7b>,
			    <0x024c 0x0cd10d68>,
			    <0x0250 0x0b9d0c37>,
			    <0x0254 0x0a700b04>,
			    <0x0258 0x095909e1>,
			    <0x025c 0x085f08d8>,
			    <0x0260 0x078407ee>,
			    <0x0264 0x06c70722>,
			    <0x0268 0x06240673>,
			    <0x026c 0x055c05dc>,
			    <0x0270 0x049004ee>,
			    <0x0274 0x03f9043f>,
			    <0x0278 0x038803bd>,
			    <0x027c 0x0332035b>,
			    <0x0280 0x02f0030f>,
			    <0x0284 0x02a602d4>,
			    <0x0288 0x02620280>,
			    <0x028c 0x02230249>,
			    <0x0290 0x01f30208>,
			    <0x0294 0x01d801e4>,
			    <0x0298 0x01c801cf>,
			    <0x029c 0x01bd01c2>,
			    <0x02a0 0x01b501b9>,
			    <0x02a4 0x01b001b2>,
			    <0x02a8 0x01ac01ae>,
			    <0x02ac 0x01a901aa>,
			    <0x02b0 0x01a601a7>,
			    <0x02b4 0x01a401a5>,
			    <0x02b8 0x01a301a4>,
			    <0x02bc 0x000001a2>,
			    <0x02c0 0x00008040>,
			    <0x02c4 0xffff0000>,
			    <0x02c8 0x00000000>,
			    <0x02cc 0x00000000>,
			    <0x02d0 0x00000000>,
			    <0x02d4 0x04230000>,
			    <0x02d8 0xa3d04eb4>,
			    <0x02dc 0xceb1bcd9>,
			    <0x02e0 0xdf3cc2af>,
			    <0x02e4 0xffffc028>,
			    <0x02e8 0x6b3fffff>,
			    <0x02ec 0x434f4424>,
			    <0x02f0 0x77854f59>,
			    <0x02f4 0x6c3d6039>,
			    <0x02f8 0x5e576f9d>,
			    <0x02fc 0x62e9607a>,
			    <0x0300 0x667768b4>,
			    <0x0304 0x6382632e>,
			    <0x0308 0x56bc5eba>,
			    <0x030c 0x51755387>,
			    <0x0310 0x59a154f7>,
			    <0x0314 0x56b3578c>,
			    <0x0318 0x54105d97>,
			    <0x031c 0x506e50cd>,
			    <0x0320 0x560c5023>,
			    <0x0324 0x4d0a5e2f>,
			    <0x0328 0x457146e5>,
			    <0x032c 0x59b54c4b>,
			    <0x0330 0x6574628f>,
			    <0x0334 0x4e9a574a>,
			    <0x0338 0x436c48bc>,
			    <0x033c 0x43f74b27>,
			    <0x0340 0x3d653eb5>,
			    <0x0344 0x3b693b24>,
			    <0x0348 0x3d403fd2>,
			    <0x034c 0x3b573cb7>,
			    <0x0350 0x369a3dca>,
			    <0x0354 0x32b833fa>,
			    <0x0358 0x30a63163>,
			    <0x035c 0x34453171>,
			    <0x0360 0x32be3755>,
			    <0x0364 0x314a30c1>,
			    <0x0368 0x32e53027>,
			    <0x036c 0x331d335c>,
			    <0x0370 0x34ac33f0>,
			    <0x0374 0x359636ae>,
			    <0x0378 0x390f36b7>,
			    <0x037c 0x311b3370>,
			    <0x0380 0x34f3357c>,
			    <0x0384 0x26592db9>,
			    <0x0388 0x231424cb>,
			    <0x038c 0x1ecb2134>,
			    <0x0390 0x18dc1c70>,
			    <0x0394 0x0fac13ac>,
			    <0x0398 0x0d550ddc>,
			    <0x039c 0x09c30ac6>,
			    <0x03a0 0x0c0f0b5a>,
			    <0x03a4 0x0b8b0bdc>,
			    <0x03a8 0x09b60a4d>,
			    <0x03ac 0x07bd0880>,
			    <0x03b0 0x07010716>,
			    <0x03b4 0x069006aa>,
			    <0x03b8 0x06270664>,
			    <0x03bc 0x04c0050b>,
			    <0x03c0 0x04f704a7>,
			    <0x03c4 0x05940575>,
			    <0x03c8 0x08320758>,
			    <0x03cc 0x0a290882>,
			    <0x03d0 0x42bc0b4f>,
			    <0x03d4 0x00000000>,
			    <0x03d8 0x00000000>,
			    <0x03dc 0x00000000>,
			    <0x03e0 0x00000000>,
			    <0x03e4 0x00000000>,
			    <0x03e8 0x00000000>,
			    <0x03ec 0x00000000>,
			    <0x03f0 0x00000000>,
			    <0x03f4 0x00000000>,
			    <0x03f8 0x00000000>,
			    <0x03fc 0x00000000>,
			    <0x0400 0x00000000>,
			    <0x0404 0x00000000>,
			    <0x0408 0x00ffffff>,
			    <0x040c 0x037415dd>,
			    <0x0410 0x00000000>,
			    <0x0414 0x00000000>,
			    <0x0418 0x10001000>,
			    <0x041c 0x00001000>,
			    <0x0420 0x00000000>,
			    <0x0424 0x00000000>,
			    <0x0428 0x00000000>,
			    <0x042c 0x00000000>,
			    <0x0430 0x00000000>,
			    <0x0434 0x00000000>,
			    <0x0438 0x00000000>,
			    <0x043c 0x00000000>,
			    <0x0440 0xfe0bffff>,
			    <0x0444 0xfa62fc2d>,
			    <0x0448 0xf704f8aa>,
			    <0x044c 0xf3e4f56d>,
			    <0x0450 0xf0fcf26a>,
			    <0x0454 0xee43ef9a>,
			    <0x0458 0xebb4ecf7>,
			    <0x045c 0xe94bea7b>,
			    <0x0460 0xe703e823>,
			    <0x0464 0xe4dae5eb>,
			    <0x0468 0xe2cbe3cf>,
			    <0x046c 0xe0d6e1ce>,
			    <0x0470 0xdef7dfe4>,
			    <0x0474 0xdd2cde0f>,
			    <0x0478 0xdb75dc4f>,
			    <0x047c 0xd9d0daa0>,
			    <0x0480 0xd83ad903>,
			    <0x0484 0xd6b4d775>,
			    <0x0488 0xd53cd5f6>,
			    <0x048c 0xd3d1d485>,
			    <0x0490 0xd272d320>,
			    <0x0494 0xd11fd1c7>,
			    <0x0498 0xcfd6d079>,
			    <0x049c 0xce98cf36>,
			    <0x04a0 0xcd63cdfc>,
			    <0x04a4 0xcc38cccc>,
			    <0x04a8 0xcb15cba5>,
			    <0x04ac 0xc9faca86>,
			    <0x04b0 0xc8e6c96f>,
			    <0x04b4 0xc7dac860>,
			    <0x04b8 0xc6d5c757>,
			    <0x04bc 0xc5d7c655>,
			    <0x04c0 0x0000c599>,
			    <0x04c4 0x00000000>,
			    <0x04c8 0x00000000>,
			    <0x04cc 0x00000000>,
			    <0x04d0 0x00000000>,
			    <0x04d4 0x00000000>,
			    <0x04d8 0x00000000>,
			    <0x04dc 0x00000000>,
			    <0x04e0 0x00000000>,
			    <0x04e4 0x00000000>,
			    <0x04e8 0x00000000>,
			    <0x04ec 0x00000000>,
			    <0x04f0 0x00000000>,
			    <0x04f4 0x00000000>,
			    <0x04f8 0x00000000>,
			    <0x04fc 0x00000000>,
			    <0x0500 0x00000000>,
			    <0x0504 0x00000000>,
			    <0x0508 0x00000000>,
			    <0x050c 0x00000000>,
			    <0x0510 0x00000000>,
			    <0x0514 0x00000000>,
			    <0x0518 0x00000000>,
			    <0x051c 0x00000000>,
			    <0x0520 0x00000000>,
			    <0x0524 0x00000000>,
			    <0x0528 0x00000000>,
			    <0x052c 0x00000000>,
			    <0x0530 0x00000000>,
			    <0x0534 0x00000000>,
			    <0x0538 0x00000000>,
			    <0x053c 0x00000000>,
			    <0x0540 0x00000000>,
			    <0x0544 0x00000000>,
			    <0x0548 0x00000000>,
			    <0x054c 0x00000000>,
			    <0x0550 0x00000000>,
			    <0x0554 0x00000000>,
			    <0x0558 0x00000000>,
			    <0x055c 0x00000000>,
			    <0x0560 0x00000000>,
			    <0x0564 0x00000000>,
			    <0x0568 0x00000000>,
			    <0x056c 0x00000000>,
			    <0x0570 0x00000000>,
			    <0x0574 0x00000000>,
			    <0x0578 0x00000000>,
			    <0x057c 0x00000000>,
			    <0x0580 0x00000000>,
			    <0x0584 0x00000000>,
			    <0x0588 0x00000000>,
			    <0x058c 0x00000000>,
			    <0x0590 0x00000000>,
			    <0x0594 0x00000000>,
			    <0x0598 0x00000000>,
			    <0x059c 0x00000000>,
			    <0x05a0 0x00000000>,
			    <0x05a4 0x00000000>,
			    <0x05a8 0x00000000>,
			    <0x05ac 0x00000000>,
			    <0x05b0 0x00000000>,
			    <0x05b4 0x00000000>,
			    <0x05b8 0x00000000>,
			    <0x05bc 0x00000000>,
			    <0x05c0 0x00000000>,
			    <0x05c4 0x00000000>,
			    <0x05c8 0x00000000>,
			    <0x05cc 0x00000000>,
			    <0x05d0 0x00000000>,
			    <0x05d4 0x00000000>,
			    <0x05d8 0x00000000>,
			    <0x05dc 0x00000000>,
			    <0x05e0 0x00000000>,
			    <0x05e4 0x00000000>,
			    <0x05e8 0x00000000>,
			    <0x05ec 0x00000000>,
			    <0x05f0 0x00400000>,
			    <0x05f4 0x00000000>,
			    <0x05f8 0x00000000>,
			    <0x05fc 0x00000000>,
			    <0x0600 0x00000000>,
			    <0x0604 0x00000000>,
			    <0x0608 0x00000000>,
			    <0x060c 0x00000000>,
			    <0x0610 0x20191230>,
			    <0x0614 0x00000000>,
			    <0x0618 0x00000000>,
			    <0x061c 0x00000000>,
			    <0x0620 0x00000000>,
			    <0x0624 0x00000000>;

			  ipe_reg_cfg = 
			    <0x0004 0x08000005>,
			    <0x0008 0x00017edb>,
			    <0x000c 0x00000010>,
			    <0x0010 0x00000000>,
			    <0x0014 0x001e0000>,
			    <0x0018 0x00000438>,
			    <0x001c 0x00000000>,
			    <0x0020 0x00000000>,
			    <0x0024 0x00000000>,
			    <0x0028 0x00000000>,
			    <0x002c 0x160dd428>,
			    <0x0030 0x00000000>,
			    <0x0034 0x00000000>,
			    <0x0038 0x00800000>,
			    <0x003c 0x00800000>,
			    <0x0040 0x00000000>,
			    <0x0044 0x00000000>,
			    <0x0048 0x10000000>,
			    <0x004c 0x00000000>,
			    <0x0050 0x00001ffe>,
			    <0x0054 0x00000000>,
			    <0x0058 0xff040001>,
			    <0x005c 0x00000000>,
			    <0x0060 0x00000000>,
			    <0x0064 0x00000000>,
			    <0x0068 0x00000000>,
			    <0x006c 0x00000000>,
			    <0x0070 0x017c05a3>,
			    <0x0074 0x3e2ec02a>,
			    <0x0078 0x00a013dd>,
			    <0x007c 0x0010100a>,
			    <0x0080 0x00181818>,
			    <0x0084 0x00000333>,
			    <0x0088 0x00010004>,
			    <0x008c 0x00008888>,
			    <0x0090 0x88881000>,
			    <0x0094 0x00082028>,
			    <0x0098 0xffc8201f>,
			    <0x009c 0x00a500b6>,
			    <0x00a0 0x00800801>,
			    <0x00a4 0xffff3180>,
			    <0x00a8 0x00010000>,
			    <0x00ac 0x01000100>,
			    <0x00b0 0x00600060>,
			    <0x00b4 0x05080000>,
			    <0x00b8 0x40352d20>,
			    <0x00bc 0x40404040>,
			    <0x00c0 0x40404040>,
			    <0x00c4 0x262c3440>,
			    <0x00c8 0x15020000>,
			    <0x00cc 0x7a573000>,
			    <0x00d0 0xffddb79a>,
			    <0x00d4 0xaac0e0ff>,
			    <0x00d8 0x8088909a>,
			    <0x00dc 0x03bb7bff>,
			    <0x00e0 0x40400001>,
			    <0x00e4 0x00000000>,
			    <0x00e8 0x00004040>,
			    <0x00ec 0x00000000>,
			    <0x00f0 0x41000804>,
			    <0x00f4 0x41000804>,
			    <0x00f8 0x41000804>,
			    <0x00fc 0x00000000>,
			    <0x0100 0x01af0001>,
			    <0x0104 0x0fe10f71>,
			    <0x0108 0x017e0f9e>,
			    <0x010c 0x00330fe5>,
			    <0x0110 0x01dc0ef1>,
			    <0x0114 0x00104080>,
			    <0x0118 0x00000000>,
			    <0x011c 0x00000000>,
			    <0x0120 0x00000000>,
			    <0x0124 0x050a0f14>,
			    <0x0128 0x00000000>,
			    <0x012c 0x00000000>,
			    <0x0130 0x0f0a0500>,
			    <0x0134 0x00000000>,
			    <0x0138 0x00752c4d>,
			    <0x013c 0x120357d5>,
			    <0x0140 0x07af2a80>,
			    <0x0144 0x00000000>,
			    <0x0148 0x28200000>,
			    <0x014c 0x80808080>,
			    <0x0150 0x80808080>,
			    <0x0154 0x80808080>,
			    <0x0158 0x80808080>,
			    <0x015c 0x80808080>,
			    <0x0160 0x80808080>,
			    <0x0164 0x00000000>,
			    <0x0168 0x00000000>,
			    <0x016c 0x00000000>,
			    <0x0170 0x00000000>,
			    <0x0174 0x00000000>,
			    <0x0178 0x00000000>,
			    <0x017c 0x00000000>,
			    <0x0180 0x00000000>,
			    <0x0184 0x00000000>,
			    <0x0188 0x00000000>,
			    <0x018c 0x00000000>,
			    <0x0190 0x00000000>,
			    <0x0194 0x80808080>,
			    <0x0198 0x80808080>,
			    <0x019c 0x80808080>,
			    <0x01a0 0x80808080>,
			    <0x01a4 0x80808080>,
			    <0x01a8 0x80808080>,
			    <0x01ac 0x00820820>,
			    <0x01b0 0x00820820>,
			    <0x01b4 0x00000000>,
			    <0x01b8 0x0002308c>,
			    <0x01bc 0x00000080>,
			    <0x01c0 0x00000000>,
			    <0x01c4 0x00000000>,
			    <0x01c8 0x00ffffff>,
			    <0x01cc 0x00808080>,
			    <0x01d0 0x80808080>,
			    <0x01d4 0x00000000>,
			    <0x01d8 0x00000000>,
			    <0x01dc 0x08020080>,
			    <0x01e0 0x08020080>,
			    <0x01e4 0x08020080>,
			    <0x01e8 0x08020080>,
			    <0x01ec 0x08020080>,
			    <0x01f0 0x00020080>,
			    <0x01f4 0x00000000>,
			    <0x01f8 0x00000000>,
			    <0x01fc 0x00000000>,
			    <0x0200 0x00000000>,
			    <0x0204 0x00000000>,
			    <0x0208 0x00000000>,
			    <0x020c 0x00000000>,
			    <0x0210 0x00000000>,
			    <0x0214 0x00000000>,
			    <0x0218 0x00000000>,
			    <0x021c 0x00000000>,
			    <0x0220 0x00000000>,
			    <0x0224 0x00000000>,
			    <0x0228 0x00000000>,
			    <0x022c 0x00000000>,
			    <0x0230 0x00000000>,
			    <0x0234 0x00000000>,
			    <0x0238 0x00000000>,
			    <0x023c 0x00000000>,
			    <0x0240 0x00000000>,
			    <0x0244 0x00000000>,
			    <0x0248 0x00000000>,
			    <0x024c 0x00000000>,
			    <0x0250 0x00000000>,
			    <0x0254 0x00000000>,
			    <0x0258 0x00000000>,
			    <0x025c 0x00000000>,
			    <0x0260 0x00000000>,
			    <0x0264 0x00000000>,
			    <0x0268 0x00000000>,
			    <0x026c 0x00000000>,
			    <0x0270 0x00000000>,
			    <0x0274 0x00000000>,
			    <0x0278 0x00000000>,
			    <0x027c 0x00000000>,
			    <0x0280 0x00000000>,
			    <0x0284 0x00000000>,
			    <0x0288 0x00000000>,
			    <0x028c 0x00000000>,
			    <0x0290 0x00000000>,
			    <0x0294 0x00000000>,
			    <0x0298 0x00000000>,
			    <0x029c 0x00000000>,
			    <0x02a0 0x00000000>,
			    <0x02a4 0x00000000>,
			    <0x02a8 0x00000000>,
			    <0x02ac 0x00000000>,
			    <0x02b0 0x00000000>,
			    <0x02b4 0x00000000>,
			    <0x02b8 0x00000000>,
			    <0x02bc 0x00000000>,
			    <0x02c0 0x0000010f>,
			    <0x02c4 0x16351600>,
			    <0x02c8 0x00000040>,
			    <0x02cc 0x16352600>,
			    <0x02d0 0x00000040>,
			    <0x02d4 0x01e50200>,
			    <0x02d8 0x1ffbb877>,
			    <0x02dc 0x21b80077>,
			    <0x02e0 0x00000000>,
			    <0x02e4 0x00000000>,
			    <0x02e8 0x00000000>,
			    <0x02ec 0x00000000>,
			    <0x02f0 0x00000054>,
			    <0x02f4 0x00000000>,
			    <0x02f8 0x00000000>,
			    <0x02fc 0x00000000>,
			    <0x0300 0x00000000>,
			    <0x0304 0x00000000>,
			    <0x0308 0x00000000>,
			    <0x030c 0x00000000>,
			    <0x0310 0x00000000>,
			    <0x0314 0x00000000>,
			    <0x0318 0x00000000>,
			    <0x031c 0x00000000>,
			    <0x0320 0x00000000>,
			    <0x0324 0x00000000>,
			    <0x0328 0x00000000>,
			    <0x032c 0x00000000>,
			    <0x0330 0x00000000>,
			    <0x0334 0x00000000>,
			    <0x0338 0x00000000>,
			    <0x033c 0x00000818>,
			    <0x0340 0x00000000>,
			    <0x0344 0x00000000>,
			    <0x0348 0x00000000>,
			    <0x034c 0x00000000>,
			    <0x0350 0x00000000>,
			    <0x0354 0x00000000>,
			    <0x0358 0x0ff200ff>,
			    <0x035c 0x000000ff>,
			    <0x0360 0x00000000>,
			    <0x0364 0x00000000>,
			    <0x0368 0x00000000>,
			    <0x036c 0x00000000>,
			    <0x0370 0x00000000>,
			    <0x0374 0x00000000>,
			    <0x0378 0x00000000>,
			    <0x037c 0x00000000>,
			    <0x0380 0x00000000>,
			    <0x0384 0x00800000>,
			    <0x0388 0x54545454>,
			    <0x038c 0x54545454>,
			    <0x0390 0x00000054>,
			    <0x0394 0x00000000>,
			    <0x0398 0x00000000>,
			    <0x039c 0x00000000>,
			    <0x03a0 0x00e00004>,
			    <0x03a4 0x4000d200>,
			    <0x03a8 0x00000000>,
			    <0x03ac 0x00000000>,
			    <0x03b0 0x00000000>,
			    <0x03b4 0x00000000>,
			    <0x03b8 0x00000000>,
			    <0x03bc 0x00000000>,
			    <0x03c0 0x00000000>,
			    <0x03c4 0x00000000>,
			    <0x03c8 0x00000000>,
			    <0x03cc 0x00000000>,
			    <0x03d0 0x00000000>,
			    <0x03d4 0x00000000>,
			    <0x03d8 0x00000000>,
			    <0x03dc 0x00000000>,
			    <0x03e0 0x00000000>,
			    <0x03e4 0x00000000>,
			    <0x03e8 0x00000000>,
			    <0x03ec 0x00000000>,
			    <0x03f0 0x00000000>,
			    <0x03f4 0x00000000>,
			    <0x03f8 0x00000000>,
			    <0x03fc 0x00000000>,
			    <0x0400 0x356d474d>,
			    <0x0404 0x2ddb5ed1>,
			    <0x0408 0x08b1ac49>,
			    <0x040c 0x27a9ce6d>,
			    <0x0410 0x0c62a48b>,
			    <0x0414 0x26d99a5f>,
			    <0x0418 0x0f1384c6>,
			    <0x041c 0x21b8520d>,
			    <0x0420 0x309c12ff>,
			    <0x0424 0x1b16999b>,
			    <0x0428 0x31dc6313>,
			    <0x042c 0x2448f636>,
			    <0x0430 0x1b16999b>,
			    <0x0434 0x0c62a48b>,
			    <0x0438 0x2368c229>,
			    <0x043c 0x2ddb5ed1>,
			    <0x0440 0x1ed791db>,
			    <0x0444 0x309c12ff>,
			    <0x0448 0x1c76f1b1>,
			    <0x044c 0x2ffbeaf4>,
			    <0x0450 0x2b9aceac>,
			    <0x0454 0x27a9ce6d>,
			    <0x0458 0x0c62a48b>,
			    <0x045c 0x2d1b2ec5>,
			    <0x0460 0x0c62a48b>,
			    <0x0464 0x1ed791db>,
			    <0x0468 0x2e8b8edd>,
			    <0x046c 0x368d935f>,
			    <0x0470 0x309c12ff>,
			    <0x0474 0x1ed791db>,
			    <0x0478 0x2b9aceac>,
			    <0x047c 0x0c62a48b>,
			    <0x0480 0x2aca9aa0>,
			    <0x0484 0x0f1384c6>,
			    <0x0488 0x22988a1b>,
			    <0x048c 0x2e8b8edd>,
			    <0x0490 0x37bddb72>,
			    <0x0494 0x19b63d82>,
			    <0x0498 0x08b1ac49>,
			    <0x049c 0x2ddb5ed1>,
			    <0x04a0 0x0c62a48b>,
			    <0x04a4 0x287a027a>,
			    <0x04a8 0x0c62a48b>,
			    <0x04ac 0x293a3687>,
			    <0x04b0 0x0f1384c6>,
			    <0x04b4 0x293a3687>,
			    <0x04b8 0x2ddb5ed1>,
			    <0x04bc 0x326c871d>,
			    <0x04c0 0x1ed791db>,
			    <0x04c4 0x313c3b09>,
			    <0x04c8 0x2448f636>,
			    <0x04cc 0x20d819fe>,
			    <0x04d0 0x2f4bbae8>,
			    <0x04d4 0x08b1ac49>,
			    <0x04d8 0x2448f636>,
			    <0x04dc 0x0c62a48b>,
			    <0x04e0 0x31dc6313>,
			    <0x04e4 0x2b9aceac>,
			    <0x04e8 0x326c871d>,
			    <0x04ec 0x21b8520d>,
			    <0x04f0 0x0c62a48b>,
			    <0x04f4 0x2b9aceac>,
			    <0x04f8 0x0c62a48b>,
			    <0x04fc 0x19b63d82>,
			    <0x0500 0x111404f1>,
			    <0x0504 0x27a9ce6d>,
			    <0x0508 0x2aca9aa0>,
			    <0x050c 0x1fe7d9ed>,
			    <0x0510 0x27a9ce6d>,
			    <0x0514 0x08b1ac49>,
			    <0x0518 0x22988a1b>,
			    <0x051c 0x0c62a48b>,
			    <0x0520 0x25f96652>,
			    <0x0524 0x1c76f1b1>,
			    <0x0528 0x2aca9aa0>,
			    <0x052c 0x25292e44>,
			    <0x0530 0x1c76f1b1>,
			    <0x0534 0x19b63d82>,
			    <0x0538 0x0c62a48b>,
			    <0x053c 0x1ed791db>,
			    <0x0540 0x0f1384c6>,
			    <0x0544 0x1fe7d9ed>,
			    <0x0548 0x1b16999b>,
			    <0x054c 0x1c76f1b1>,
			    <0x0550 0x0c62a48b>,
			    <0x0554 0x22988a1b>,
			    <0x0558 0x0c62a48b>,
			    <0x055c 0x19b63d82>,
			    <0x0560 0x1c76f1b1>,
			    <0x0564 0x14d4f930>,
			    <0x0568 0x1c76f1b1>,
			    <0x056c 0x25292e44>,
			    <0x0570 0x2e8b8edd>,
			    <0x0574 0x2e8b8edd>,
			    <0x0578 0x1ed791db>,
			    <0x057c 0x25f96652>,
			    <0x0580 0x2aca9aa0>,
			    <0x0584 0x08b1ac49>,
			    <0x0588 0x19b63d82>,
			    <0x058c 0x08b1ac49>,
			    <0x0590 0x25292e44>,
			    <0x0594 0x1fe7d9ed>,
			    <0x0598 0x20d819fe>,
			    <0x059c 0x1c76f1b1>,
			    <0x05a0 0x0c62a48b>,
			    <0x05a4 0x1db745c7>,
			    <0x05a8 0x1c76f1b1>,
			    <0x05ac 0x2c5afeb9>,
			    <0x05b0 0x22988a1b>,
			    <0x05b4 0x1db745c7>,
			    <0x05b8 0x2368c229>,
			    <0x05bc 0x08b1ac49>,
			    <0x05c0 0x1b16999b>,
			    <0x05c4 0x08b1ac49>,
			    <0x05c8 0x1825d568>,
			    <0x05cc 0x1fe7d9ed>,
			    <0x05d0 0x309c12ff>,
			    <0x05d4 0x2ddb5ed1>,
			    <0x05d8 0x1ed791db>,
			    <0x05dc 0x14d4f930>,
			    <0x05e0 0x08b1ac49>,
			    <0x05e4 0x19b63d82>,
			    <0x05e8 0x25f96652>,
			    <0x05ec 0x25f96652>,
			    <0x05f0 0x1fe7d9ed>,
			    <0x05f4 0x1c76f1b1>,
			    <0x05f8 0x2ddb5ed1>,
			    <0x05fc 0x0c62a48b>,
			    <0x0600 0x1b16999b>,
			    <0x0604 0x0c62a48b>,
			    <0x0608 0x2448f636>,
			    <0x060c 0x1c76f1b1>,
			    <0x0610 0x2448f636>,
			    <0x0614 0x1db745c7>,
			    <0x0618 0x1fe7d9ed>,
			    <0x061c 0x2448f636>,
			    <0x0620 0x0f1384c6>,
			    <0x0624 0x21b8520d>,
			    <0x0628 0x1b16999b>,
			    <0x062c 0x2c5afeb9>,
			    <0x0630 0x22988a1b>,
			    <0x0634 0x21b8520d>,
			    <0x0638 0x19b63d82>,
			    <0x063c 0x08b1ac49>,
			    <0x0640 0x21b8520d>,
			    <0x0644 0x1ed791db>,
			    <0x0648 0x293a3687>,
			    <0x064c 0x1c76f1b1>,
			    <0x0650 0x2a0a6a93>,
			    <0x0654 0x1b16999b>,
			    <0x0658 0x2448f636>,
			    <0x065c 0x14d4f930>,
			    <0x0660 0x0c62a48b>,
			    <0x0664 0x1c76f1b1>,
			    <0x0668 0x0f1384c6>,
			    <0x066c 0x22988a1b>,
			    <0x0670 0x20d819fe>,
			    <0x0674 0x287a027a>,
			    <0x0678 0x2c5afeb9>,
			    <0x067c 0x2b9aceac>,
			    <0x0680 0x22988a1b>,
			    <0x0684 0x2aca9aa0>,
			    <0x0688 0x2448f636>,
			    <0x068c 0x0c62a48b>,
			    <0x0690 0x22988a1b>,
			    <0x0694 0x0f1384c6>,
			    <0x0698 0x20d819fe>,
			    <0x069c 0x20d819fe>,
			    <0x06a0 0x2b9aceac>,
			    <0x06a4 0x1ed791db>,
			    <0x06a8 0x35fd6f56>,
			    <0x06ac 0x2448f636>,
			    <0x06b0 0x3f7fcfef>,
			    <0x06b4 0x14d4f930>,
			    <0x06b8 0x0f1384c6>,
			    <0x06bc 0x1c76f1b1>,
			    <0x06c0 0x111404f1>,
			    <0x06c4 0x287a027a>,
			    <0x06c8 0x1c76f1b1>,
			    <0x06cc 0x3fffeff7>,
			    <0x06d0 0x25f96652>,
			    <0x06d4 0x0f1384c6>,
			    <0x06d8 0x3d0f33c8>,
			    <0x06dc 0x22988a1b>,
			    <0x06e0 0x3fffeff7>,
			    <0x06e4 0x21b8520d>,
			    <0x06e8 0x3fffeff7>,
			    <0x06ec 0x2448f636>,
			    <0x06f0 0x3f7fcfef>,
			    <0x06f4 0x3a6e8b9e>,
			    <0x06f8 0x25292e44>,
			    <0x06fc 0x3fffeff7>,
			    <0x0700 0x00000000>,
			    <0x0704 0x00000000>,
			    <0x0708 0x00000000>,
			    <0x070c 0x00000000>,
			    <0x0710 0x00000000>,
			    <0x0714 0x00000000>,
			    <0x0718 0x00000000>,
			    <0x071c 0x00000000>,
			    <0x0720 0x00000000>,
			    <0x0724 0x00000000>,
			    <0x0728 0x00000000>,
			    <0x072c 0x00000000>,
			    <0x0730 0x00000000>,
			    <0x0734 0x00000000>,
			    <0x0738 0x00000000>,
			    <0x073c 0x00000000>,
			    <0x0740 0x00000000>,
			    <0x0744 0x00000000>,
			    <0x0748 0x00000000>,
			    <0x074c 0x00000000>,
			    <0x0750 0x00000000>,
			    <0x0754 0x00000000>,
			    <0x0758 0x00000000>,
			    <0x075c 0x00000000>,
			    <0x0760 0x00000000>,
			    <0x0764 0x00000000>,
			    <0x0768 0x00000000>,
			    <0x076c 0x00000000>,
			    <0x0770 0x00000000>,
			    <0x0774 0x00000000>,
			    <0x0778 0x00000000>,
			    <0x077c 0x00000000>,
			    <0x0780 0x00000000>,
			    <0x0784 0x00000000>,
			    <0x0788 0x00000000>,
			    <0x078c 0x00000000>,
			    <0x0790 0x00000000>,
			    <0x0794 0x00000000>,
			    <0x0798 0x00000000>,
			    <0x079c 0x00000000>,
			    <0x07a0 0x00000000>,
			    <0x07a4 0x00000000>,
			    <0x07a8 0x00000000>,
			    <0x07ac 0x00000000>,
			    <0x07b0 0x00000000>,
			    <0x07b4 0x00000000>,
			    <0x07b8 0x00000000>,
			    <0x07bc 0x00000000>,
			    <0x07c0 0x00000000>,
			    <0x07c4 0x00000000>,
			    <0x07c8 0x00000000>,
			    <0x07cc 0x00000000>,
			    <0x07d0 0x00000000>,
			    <0x07d4 0x00000000>,
			    <0x07d8 0x00000000>,
			    <0x07dc 0x00000000>,
			    <0x07e0 0x00000000>,
			    <0x07e4 0x00000000>,
			    <0x07e8 0x00000000>,
			    <0x07ec 0x00000000>,
			    <0x07f0 0x00000000>,
			    <0x07f4 0x00000000>,
			    <0x07f8 0x00000000>,
			    <0x07fc 0x00000000>,
			    <0x0800 0x08b12400>,
			    <0x0804 0x1113c4c6>,
			    <0x0808 0x16853530>,
			    <0x080c 0x1b166d82>,
			    <0x0810 0x1ed76dc7>,
			    <0x0814 0x21b835fe>,
			    <0x0818 0x2448da29>,
			    <0x081c 0x26d97e52>,
			    <0x0820 0x293a1e7a>,
			    <0x0824 0x2b9ab2a0>,
			    <0x0828 0x2ddb46c5>,
			    <0x082c 0x2ffbd2e8>,
			    <0x0830 0x31dc4f09>,
			    <0x0834 0x33acc326>,
			    <0x0838 0x356d3743>,
			    <0x083c 0x372da35f>,
			    <0x0840 0x38ce137b>,
			    <0x0844 0x3a6e7b95>,
			    <0x0848 0x3bfedfaf>,
			    <0x084c 0x3d8f43c8>,
			    <0x0850 0x3effa3e0>,
			    <0x0854 0x000ffff7>,
			    <0x0858 0x00000000>,
			    <0x085c 0x00000000>,
			    <0x0860 0x00000000>,
			    <0x0864 0x00000000>,
			    <0x0868 0x00000000>,
			    <0x086c 0x00000000>,
			    <0x0870 0x00000000>,
			    <0x0874 0x00000000>,
			    <0x0878 0x00000000>,
			    <0x087c 0x00000000>,
			    <0x0880 0x00000000>,
			    <0x0884 0x00000000>,
			    <0x0888 0x00000000>,
			    <0x088c 0x00000000>,
			    <0x0890 0x00000000>,
			    <0x0894 0x00000000>,
			    <0x0898 0x00000000>,
			    <0x089c 0x00000000>,
			    <0x08a0 0x00000000>,
			    <0x08a4 0x00000000>,
			    <0x08a8 0x00000000>,
			    <0x08ac 0x00000000>,
			    <0x08b0 0x00000000>,
			    <0x08b4 0x00000000>,
			    <0x08b8 0x00000000>,
			    <0x08bc 0x00000000>,
			    <0x08c0 0x00000000>,
			    <0x08c4 0x00000000>,
			    <0x08c8 0x00000000>,
			    <0x08cc 0x00000000>,
			    <0x08d0 0x00000000>,
			    <0x08d4 0x00000000>,
			    <0x08d8 0x00000000>,
			    <0x08dc 0x00000000>,
			    <0x08e0 0x00000000>,
			    <0x08e4 0x00000000>,
			    <0x08e8 0x00000000>,
			    <0x08ec 0x00000000>,
			    <0x08f0 0x00000000>,
			    <0x08f4 0x00000000>,
			    <0x08f8 0x00000000>,
			    <0x08fc 0x00000000>;

			  ime_reg_cfg = 
			    <0x0004 0x0a00340e>,
			    <0x0008 0x00000000>,
			    <0x000c 0x80000000>,
			    <0x0010 0x00000000>,
			    <0x0014 0x00000000>,
			    <0x0018 0xa0000040>,
			    <0x001c 0x40000030>,
			    <0x0020 0x04380780>,
			    <0x0024 0x000000f0>,
			    <0x0028 0x001e0000>,
			    <0x002c 0x7f3f0438>,
			    <0x0030 0x00000140>,
			    <0x0034 0x00000140>,
			    <0x0038 0x003c0000>,
			    <0x003c 0x003d2c00>,
			    <0x0040 0x003e5800>,
			    <0x0044 0x00000000>,
			    <0x0048 0x00000000>,
			    <0x004c 0x00000000>,
			    <0x0050 0x00000000>,
			    <0x0054 0x00000000>,
			    <0x0058 0x00000000>,
			    <0x005c 0x00000000>,
			    <0x0060 0x00000012>,
			    <0x0064 0x00000000>,
			    <0x0068 0x00000000>,
			    <0x006c 0x00000000>,
			    <0x0070 0x00000000>,
			    <0x0074 0x00000000>,
			    <0x0078 0x00000000>,
			    <0x007c 0x04380780>,
			    <0x0080 0x00000000>,
			    <0x0084 0x04380780>,
			    <0x0088 0xff00ff00>,
			    <0x008c 0x00000780>,
			    <0x0090 0x00000780>,
			    <0x0094 0x139e7000>,
			    <0x0098 0x13be1400>,
			    <0x009c 0x13be1400>,
			    <0x00a0 0x00000000>,
			    <0x00a4 0x00000000>,
			    <0x00a8 0x00000000>,
			    <0x00ac 0x00000000>,
			    <0x00b0 0x0000001e>,
			    <0x00b4 0x1aef8088>,
			    <0x00b8 0x40ab00cd>,
			    <0x00bc 0x02410301>,
			    <0x00c0 0x071c0555>,
			    <0x00c4 0x07190554>,
			    <0x00c8 0x07160552>,
			    <0x00cc 0x00020400>,
			    <0x00d0 0x00000000>,
			    <0x00d4 0x00000000>,
			    <0x00d8 0x00000000>,
			    <0x00dc 0x00000000>,
			    <0x00e0 0x00000000>,
			    <0x00e4 0x00000000>,
			    <0x00e8 0x00000000>,
			    <0x00ec 0x00000000>,
			    <0x00f0 0x00000000>,
			    <0x00f4 0x00000000>,
			    <0x00f8 0x00000000>,
			    <0x00fc 0x00000000>,
			    <0x0100 0x00000000>,
			    <0x0104 0x01e00280>,
			    <0x0108 0x00000000>,
			    <0x010c 0x01e00280>,
			    <0x0110 0xff00ff00>,
			    <0x0114 0x00000280>,
			    <0x0118 0x00000280>,
			    <0x011c 0x145c8000>,
			    <0x0120 0x14613000>,
			    <0x0124 0x00000000>,
			    <0x0128 0x00000000>,
			    <0x012c 0x00000000>,
			    <0x0130 0x0000001e>,
			    <0x0134 0x11f78184>,
			    <0x0138 0x83bf0044>,
			    <0x013c 0x04840201>,
			    <0x0140 0x038c0800>,
			    <0x0144 0x038b07fc>,
			    <0x0148 0x038a07f8>,
			    <0x014c 0x00040200>,
			    <0x0150 0x00000000>,
			    <0x0154 0x00000000>,
			    <0x0158 0x00000000>,
			    <0x015c 0x00000000>,
			    <0x0160 0x00000000>,
			    <0x0164 0x00000000>,
			    <0x0168 0x00000000>,
			    <0x016c 0x00000000>,
			    <0x0170 0x00000000>,
			    <0x0174 0x00000000>,
			    <0x0178 0x00000000>,
			    <0x017c 0x00000000>,
			    <0x0180 0x00000000>,
			    <0x0184 0x00f003c0>,
			    <0x0188 0x00000000>,
			    <0x018c 0x00f003c0>,
			    <0x0190 0xff00ff00>,
			    <0x0194 0x000003c0>,
			    <0x0198 0x000003c0>,
			    <0x019c 0x133f7000>,
			    <0x01a0 0x1342f400>,
			    <0x01a4 0x00000000>,
			    <0x01a8 0x00000000>,
			    <0x01ac 0x00000000>,
			    <0x01b0 0x00000112>,
			    <0x01b4 0x00000000>,
			    <0x01b8 0x00000000>,
			    <0x01bc 0x00000000>,
			    <0x01c0 0x00f00140>,
			    <0x01c4 0x00000000>,
			    <0x01c8 0x00f00140>,
			    <0x01cc 0x0000ff00>,
			    <0x01d0 0x00000050>,
			    <0x01d4 0x00000000>,
			    <0x01d8 0x00499bc0>,
			    <0x01dc 0x00000000>,
			    <0x01e0 0x00000000>,
			    <0x01e4 0x00000000>,
			    <0x01e8 0x00000000>,
			    <0x01ec 0x00000000>,
			    <0x01f0 0x00000000>,
			    <0x01f4 0x00000000>,
			    <0x01f8 0x00000000>,
			    <0x01fc 0x00000000>,
			    <0x0200 0x00000000>,
			    <0x0204 0x00000000>,
			    <0x0208 0x00000000>,
			    <0x020c 0x00000000>,
			    <0x0210 0x00000000>,
			    <0x0214 0x00000000>,
			    <0x0218 0x00000000>,
			    <0x021c 0x00000000>,
			    <0x0220 0x011001e0>,
			    <0x0224 0x404b3fe6>,
			    <0x0228 0x00000140>,
			    <0x022c 0x012b1f00>,
			    <0x0230 0x00000004>,
			    <0x0234 0x00007e82>,
			    <0x0238 0x0002000a>,
			    <0x023c 0x00000bff>,
			    <0x0240 0x0002000a>,
			    <0x0244 0x00200022>,
			    <0x0248 0x0200000a>,
			    <0x024c 0x00000000>,
			    <0x0250 0x8000010c>,
			    <0x0254 0xfb46019a>,
			    <0x0258 0x03fc0402>,
			    <0x025c 0x040503ff>,
			    <0x0260 0x040403fe>,
			    <0x0264 0x040303fd>,
			    <0x0268 0x000005a0>,
			    <0x026c 0x162a7a00>,
			    <0x0270 0x00000505>,
			    <0x0274 0x00000000>,
			    <0x0278 0x00000000>,
			    <0x027c 0x00000000>,
			    <0x0280 0x00008080>,
			    <0x0284 0x16c6b9f0>,
			    <0x0288 0x0a63a12a>,
			    <0x028c 0x00008864>,
			    <0x0290 0x16c6b9f0>,
			    <0x0294 0x0a63a12a>,
			    <0x0298 0x00008864>,
			    <0x029c 0x00000000>,
			    <0x02a0 0x00000000>,
			    <0x02a4 0x00000000>,
			    <0x02a8 0x00000000>,
			    <0x02ac 0x00000000>,
			    <0x02b0 0x00000000>,
			    <0x02b4 0x00000000>,
			    <0x02b8 0x00000000>,
			    <0x02bc 0x00000000>,
			    <0x02c0 0x00000000>,
			    <0x02c4 0x00000000>,
			    <0x02c8 0x00000000>,
			    <0x02cc 0x00000000>,
			    <0x02d0 0x00000000>,
			    <0x02d4 0x00000000>,
			    <0x02d8 0x00000000>,
			    <0x02dc 0x00000000>,
			    <0x02e0 0x00000000>,
			    <0x02e4 0x00000000>,
			    <0x02e8 0x00000000>,
			    <0x02ec 0x00000000>,
			    <0x02f0 0x00000000>,
			    <0x02f4 0x00000000>,
			    <0x02f8 0x00000000>,
			    <0x02fc 0x00000000>,
			    <0x0300 0x00000000>,
			    <0x0304 0x00000000>,
			    <0x0308 0x00000000>,
			    <0x030c 0x00000000>,
			    <0x0310 0x00000000>,
			    <0x0314 0x00000000>,
			    <0x0318 0x00000000>,
			    <0x031c 0x00000000>,
			    <0x0320 0x00000000>,
			    <0x0324 0x00000000>,
			    <0x0328 0x00000000>,
			    <0x032c 0x00000000>,
			    <0x0330 0x00000000>,
			    <0x0334 0x00000000>,
			    <0x0338 0x00000000>,
			    <0x033c 0x00000000>,
			    <0x0340 0x00000000>,
			    <0x0344 0x00000000>,
			    <0x0348 0x00000000>,
			    <0x034c 0x00000000>,
			    <0x0350 0x00000000>,
			    <0x0354 0x00000000>,
			    <0x0358 0x00000000>,
			    <0x035c 0x00000000>,
			    <0x0360 0x00000000>,
			    <0x0364 0x00000000>,
			    <0x0368 0x00000000>,
			    <0x036c 0x00000000>,
			    <0x0370 0x00000000>,
			    <0x0374 0x00000000>,
			    <0x0378 0x00000000>,
			    <0x037c 0x00000000>,
			    <0x0380 0x00000000>,
			    <0x0384 0x00000000>,
			    <0x0388 0x00000000>,
			    <0x038c 0x00000000>,
			    <0x0390 0x00000000>,
			    <0x0394 0x00000000>,
			    <0x0398 0x00000000>,
			    <0x039c 0x00000000>,
			    <0x03a0 0x00000000>,
			    <0x03a4 0x00000000>,
			    <0x03a8 0x00000000>,
			    <0x03ac 0x00000000>,
			    <0x03b0 0x00000000>,
			    <0x03b4 0x00000000>,
			    <0x03b8 0x00000000>,
			    <0x03bc 0x00000000>,
			    <0x03c0 0x00000000>,
			    <0x03c4 0x00000000>,
			    <0x03c8 0x00000000>,
			    <0x03cc 0x00000000>,
			    <0x03d0 0x00000000>,
			    <0x03d4 0x00000000>,
			    <0x03d8 0x00000000>,
			    <0x03dc 0x00000000>,
			    <0x03e0 0x00000000>,
			    <0x03e4 0x00000000>,
			    <0x03e8 0x00000000>,
			    <0x03ec 0x00000000>,
			    <0x03f0 0x00000000>,
			    <0x03f4 0x00000000>,
			    <0x03f8 0x00000000>,
			    <0x03fc 0x00000000>,
			    <0x0400 0x00000000>,
			    <0x0404 0x00000000>,
			    <0x0408 0x00000000>,
			    <0x040c 0x00000000>,
			    <0x0410 0x00000000>,
			    <0x0414 0x00000000>,
			    <0x0418 0x00000000>,
			    <0x041c 0x00000000>,
			    <0x0420 0x00000000>,
			    <0x0424 0x00000000>,
			    <0x0428 0x00000000>,
			    <0x042c 0x00000000>,
			    <0x0430 0x00000000>,
			    <0x0434 0x00000000>,
			    <0x0438 0x00000000>,
			    <0x043c 0x00000000>,
			    <0x0440 0x00000000>,
			    <0x0444 0x00000000>,
			    <0x0448 0x00000000>,
			    <0x044c 0x00000000>,
			    <0x0450 0x00000000>,
			    <0x0454 0x00000000>,
			    <0x0458 0x00000000>,
			    <0x045c 0x00000000>,
			    <0x0460 0x00000000>,
			    <0x0464 0x00000000>,
			    <0x0468 0x00000000>,
			    <0x046c 0x00000000>,
			    <0x0470 0x00000000>,
			    <0x0474 0x00000000>,
			    <0x0478 0x00000000>,
			    <0x047c 0x00000000>,
			    <0x0480 0x00000000>,
			    <0x0484 0x00000000>,
			    <0x0488 0x00000000>,
			    <0x048c 0x00000000>,
			    <0x0490 0x00000000>,
			    <0x0494 0x00000000>,
			    <0x0498 0x00000000>,
			    <0x049c 0x00000000>,
			    <0x04a0 0x00000000>,
			    <0x04a4 0x00000000>,
			    <0x04a8 0x00000000>,
			    <0x04ac 0x00000000>,
			    <0x04b0 0x00000000>,
			    <0x04b4 0x00000000>,
			    <0x04b8 0x00000000>,
			    <0x04bc 0x00000000>,
			    <0x04c0 0x00000000>,
			    <0x04c4 0x00000000>,
			    <0x04c8 0x00000000>,
			    <0x04cc 0x00000000>,
			    <0x04d0 0x00000000>,
			    <0x04d4 0x00000000>,
			    <0x04d8 0x00000000>,
			    <0x04dc 0x00000000>,
			    <0x04e0 0x00000000>,
			    <0x04e4 0x00000000>,
			    <0x04e8 0x00000000>,
			    <0x04ec 0x00000000>,
			    <0x04f0 0x00000000>,
			    <0x04f4 0x00000000>,
			    <0x04f8 0x00000000>,
			    <0x04fc 0x00000000>,
			    <0x0500 0x00000000>,
			    <0x0504 0x00000000>,
			    <0x0508 0x00000000>,
			    <0x050c 0x00000000>,
			    <0x0510 0x00000000>,
			    <0x0514 0x00000000>,
			    <0x0518 0x00000000>,
			    <0x051c 0x00000000>,
			    <0x0520 0x00000000>,
			    <0x0524 0x00000000>,
			    <0x0528 0x00000000>,
			    <0x052c 0x00000000>,
			    <0x0530 0x00000000>,
			    <0x0534 0x00000000>,
			    <0x0538 0x00000000>,
			    <0x053c 0x00000000>,
			    <0x0540 0x00000000>,
			    <0x0544 0x00000000>,
			    <0x0548 0x00000000>,
			    <0x054c 0x00000000>,
			    <0x0550 0x00000000>,
			    <0x0554 0x00000000>,
			    <0x0558 0x00000000>,
			    <0x055c 0x00000001>,
			    <0x0560 0x011001e0>,
			    <0x0564 0x00000001>,
			    <0x0568 0x00000000>,
			    <0x056c 0x00000000>,
			    <0x0570 0x01e00fff>,
			    <0x0574 0x00000000>,
			    <0x0578 0x00000000>,
			    <0x057c 0x00000000>,
			    <0x0580 0x00000000>,
			    <0x0584 0x00000000>,
			    <0x0588 0x00000000>,
			    <0x058c 0x00000000>,
			    <0x0590 0x00000000>,
			    <0x0594 0x00000000>,
			    <0x0598 0x00000000>,
			    <0x059c 0x00000000>,
			    <0x05a0 0x0438077f>,
			    <0x05a4 0x01e0027f>,
			    <0x05a8 0x00000000>,
			    <0x05ac 0x00000000>,
			    <0x05b0 0x00000000>,
			    <0x05b4 0x04380780>,
			    <0x05b8 0x04380780>,
			    <0x05bc 0x00000000>,
			    <0x05c0 0x00000000>,
			    <0x05c4 0x00000000>,
			    <0x05c8 0x00000000>,
			    <0x05cc 0x00000000>,
			    <0x05d0 0x00000000>,
			    <0x05d4 0x00000000>,
			    <0x05d8 0x00000000>,
			    <0x05dc 0x00000000>,
			    <0x05e0 0x00000000>,
			    <0x05e4 0x00000000>,
			    <0x05e8 0x00000000>,
			    <0x05ec 0x00000000>,
			    <0x05f0 0x00000000>,
			    <0x05f4 0x00000000>,
			    <0x05f8 0x00000000>,
			    <0x05fc 0x00000000>,
			    <0x0600 0x80308f62>,
			    <0x0604 0x00080000>,
			    <0x0608 0x00000000>,
			    <0x060c 0x00000000>,
			    <0x0610 0x00000000>,
			    <0x0614 0x00000000>,
			    <0x0618 0x00000000>,
			    <0x061c 0x028c8b11>,
			    <0x0620 0x0000009c>,
			    <0x0624 0x00000000>,
			    <0x0628 0x0000d836>,
			    <0x062c 0x06c1b06c>,
			    <0x0630 0x00025495>,
			    <0x0634 0x06060606>,
			    <0x0638 0x08070706>,
			    <0x063c 0x00000080>,
			    <0x0640 0x44444344>,
			    <0x0644 0x0010333f>,
			    <0x0648 0x00003fff>,
			    <0x064c 0x00000000>,
			    <0x0650 0x00000000>,
			    <0x0654 0x00000000>,
			    <0x0658 0x00000000>,
			    <0x065c 0x00000000>,
			    <0x0660 0x09080809>,
			    <0x0664 0x07070707>,
			    <0x0668 0x003b0045>,
			    <0x066c 0x003b003b>,
			    <0x0670 0x00310031>,
			    <0x0674 0x00310031>,
			    <0x0678 0x00310032>,
			    <0x067c 0x00340033>,
			    <0x0680 0x003a003a>,
			    <0x0684 0x003b003b>,
			    <0x0688 0x00001008>,
			    <0x068c 0x00000000>,
			    <0x0690 0x00000000>,
			    <0x0694 0x00000000>,
			    <0x0698 0x00000000>,
			    <0x069c 0x00000000>,
			    <0x06a0 0x01900190>,
			    <0x06a4 0x01900190>,
			    <0x06a8 0x051401f4>,
			    <0x06ac 0x05140514>,
			    <0x06b0 0x09080809>,
			    <0x06b4 0x07070707>,
			    <0x06b8 0x003b0045>,
			    <0x06bc 0x003b003b>,
			    <0x06c0 0x00310031>,
			    <0x06c4 0x00310031>,
			    <0x06c8 0x00310032>,
			    <0x06cc 0x00340033>,
			    <0x06d0 0x003a003a>,
			    <0x06d4 0x003b003b>,
			    <0x06d8 0x00001008>,
			    <0x06dc 0x00000000>,
			    <0x06e0 0x00000000>,
			    <0x06e4 0x00000000>,
			    <0x06e8 0x00000000>,
			    <0x06ec 0x00000000>,
			    <0x06f0 0x00001008>,
			    <0x06f4 0x00000000>,
			    <0x06f8 0x00000000>,
			    <0x06fc 0x00000000>,
			    <0x0700 0x00000000>,
			    <0x0704 0x00000000>,
			    <0x0708 0x00000000>,
			    <0x070c 0x00000000>,
			    <0x0710 0x00001008>,
			    <0x0714 0x00000000>,
			    <0x0718 0x00000000>,
			    <0x071c 0x00000000>,
			    <0x0720 0x00000000>,
			    <0x0724 0x00000000>,
			    <0x0728 0x00000000>,
			    <0x072c 0x00000000>,
			    <0x0730 0x3fff0403>,
			    <0x0734 0x0000e6b4>,
			    <0x0738 0x04000200>,
			    <0x073c 0x00640168>,
			    <0x0740 0x00000000>,
			    <0x0744 0x00000000>,
			    <0x0748 0x00000000>,
			    <0x074c 0x00000000>,
			    <0x0750 0x00000000>,
			    <0x0754 0x00000000>,
			    <0x0758 0x00000000>,
			    <0x075c 0x00000000>,
			    <0x0760 0x00ff0603>,
			    <0x0764 0x018000c0>,
			    <0x0768 0x00000000>,
			    <0x076c 0x00000001>,
			    <0x0770 0x20201010>,
			    <0x0774 0x00000000>,
			    <0x0778 0x00000000>,
			    <0x077c 0x00000000>,
			    <0x0780 0x00000000>,
			    <0x0784 0x00000000>,
			    <0x0788 0x00000000>,
			    <0x078c 0x00000000>,
			    <0x0790 0x10101010>,
			    <0x0794 0x10101010>,
			    <0x0798 0x00000000>,
			    <0x079c 0x00000000>,
			    <0x07a0 0x00000000>,
			    <0x07a4 0x00000000>,
			    <0x07a8 0x00000000>,
			    <0x07ac 0x00000000>,
			    <0x07b0 0x20100804>,
			    <0x07b4 0x00000000>,
			    <0x07b8 0x00000000>,
			    <0x07bc 0x00000000>,
			    <0x07c0 0x14004080>,
			    <0x07c4 0x00209632>,
			    <0x07c8 0x01f401f4>,
			    <0x07cc 0x1c181008>,
			    <0x07d0 0x1b130b00>,
			    <0x07d4 0x3a312b23>,
			    <0x07d8 0x1e150d00>,
			    <0x07dc 0x3c312923>,
			    <0x07e0 0x00004080>,
			    <0x07e4 0x00000000>,
			    <0x07e8 0x00000000>,
			    <0x07ec 0x00000000>,
			    <0x07f0 0x00000000>,
			    <0x07f4 0x00000000>,
			    <0x07f8 0x00000000>,
			    <0x07fc 0x00000000>,
			    <0x0800 0x00000780>,
			    <0x0804 0x00000780>,
			    <0x0808 0x13fd7000>,
			    <0x080c 0x141d1400>,
			    <0x0810 0x00000000>,
			    <0x0814 0x00000000>,
			    <0x0818 0x00000000>,
			    <0x081c 0x00000000>,
			    <0x0820 0x00000010>,
			    <0x0824 0x16346500>,
			    <0x0828 0x00000000>,
			    <0x082c 0x16346940>,
			    <0x0830 0x00000010>,
			    <0x0834 0x163471c0>,
			    <0x0838 0x000001e0>,
			    <0x083c 0x16307400>,
			    <0x0840 0x00000000>,
			    <0x0844 0x16326c80>,
			    <0x0848 0x00000000>,
			    <0x084c 0x00000000>,
			    <0x0850 0x00000000>,
			    <0x0854 0x00000000>,
			    <0x0858 0x00000000>,
			    <0x085c 0x00000000>,
			    <0x0860 0x00000000>,
			    <0x0864 0x00000000>,
			    <0x0868 0x00000000>,
			    <0x086c 0x00000000>,
			    <0x0870 0x00000000>,
			    <0x0874 0x00000000>,
			    <0x0878 0x00000000>,
			    <0x087c 0x00000000>,
			    <0x0880 0x00000000>,
			    <0x0884 0x00000000>,
			    <0x0888 0x00000000>,
			    <0x088c 0x00000000>,
			    <0x0890 0x00000000>,
			    <0x0894 0x00000000>,
			    <0x0898 0x00000000>,
			    <0x089c 0x00000000>,
			    <0x08a0 0x00000000>,
			    <0x08a4 0x00000000>,
			    <0x08a8 0x00000000>,
			    <0x08ac 0x00000000>,
			    <0x08b0 0x00000000>,
			    <0x08b4 0x00000000>,
			    <0x08b8 0x00000000>,
			    <0x08bc 0x00000000>,
			    <0x08c0 0x00000000>,
			    <0x08c4 0x00000000>,
			    <0x08c8 0x00000000>,
			    <0x08cc 0x00000000>,
			    <0x08d0 0x00000000>,
			    <0x08d4 0x00000000>,
			    <0x08d8 0x00000000>,
			    <0x08dc 0x00000000>,
			    <0x08e0 0x00000000>,
			    <0x08e4 0x00000000>,
			    <0x08e8 0x00000000>,
			    <0x08ec 0x00000000>,
			    <0x08f0 0x00000000>,
			    <0x08f4 0x00000000>,
			    <0x08f8 0x00000000>,
			    <0x08fc 0x00000000>,
			    <0x0900 0x00000000>,
			    <0x0904 0x00000000>,
			    <0x0908 0x00000000>,
			    <0x090c 0x00000000>,
			    <0x0910 0x0bb41249>,
			    <0x0914 0x00000748>,
			    <0x0918 0x08e80e39>,
			    <0x091c 0x000005a6>,
			    <0x0920 0x08080ccd>,
			    <0x0924 0x0000051f>,
			    <0x0928 0x07500ba3>,
			    <0x092c 0x000004ae>,
			    <0x0930 0x063509d9>,
			    <0x0934 0x000003f3>,
			    <0x0938 0x05c50925>,
			    <0x093c 0x000003a4>,
			    <0x0940 0x050f0800>,
			    <0x0944 0x00000336>,
			    <0x0948 0x0480071c>,
			    <0x094c 0x000002d9>,
			    <0x0950 0x040e0666>,
			    <0x0954 0x0000028f>,
			    <0x0958 0x03b105d1>,
			    <0x095c 0x00000253>,
			    <0x0960 0x031a04ec>,
			    <0x0964 0x000001f9>,
			    <0x0968 0x02e20492>,
			    <0x096c 0x000001d5>,
			    <0x0970 0x02870400>,
			    <0x0974 0x00000199>,
			    <0x0978 0x0240038e>,
			    <0x097c 0x0000016d>,
			    <0x0980 0x02070333>,
			    <0x0984 0x00000148>,
			    <0x0988 0x01730249>,
			    <0x098c 0x000000ea>,
			    <0x0990 0x00e30124>,
			    <0x0994 0x00ba00cc>,
			    <0x0998 0x0092009d>,
			    <0x099c 0x00720080>,
			    <0x09a0 0x005d0066>,
			    <0x09a4 0x0049004f>,
			    <0x09a8 0x00390040>,
			    <0x09ac 0x00250033>,
			    <0x09b0 0x00000000>,
			    <0x09b4 0x00000000>,
			    <0x09b8 0x00000000>,
			    <0x09bc 0x00000000>,
			    <0x09c0 0x0023001c>,
			    <0x09c4 0x0000002d>,
			    <0x09c8 0x002e0024>,
			    <0x09cc 0x0000003a>,
			    <0x09d0 0x00330028>,
			    <0x09d4 0x00000040>,
			    <0x09d8 0x0038002c>,
			    <0x09dc 0x00000046>,
			    <0x09e0 0x00420034>,
			    <0x09e4 0x00000053>,
			    <0x09e8 0x00470038>,
			    <0x09ec 0x0000005a>,
			    <0x09f0 0x00510040>,
			    <0x09f4 0x00000066>,
			    <0x09f8 0x005b0048>,
			    <0x09fc 0x00000073>,
			    <0x0a00 0x00650050>,
			    <0x0a04 0x00000080>,
			    <0x0a08 0x006f0058>,
			    <0x0a0c 0x0000008d>,
			    <0x0a10 0x00840068>,
			    <0x0a14 0x000000a6>,
			    <0x0a18 0x008e0070>,
			    <0x0a1c 0x000000b3>,
			    <0x0a20 0x00a20080>,
			    <0x0a24 0x000000cd>,
			    <0x0a28 0x00b60090>,
			    <0x0a2c 0x000000e6>,
			    <0x0a30 0x00ca00a0>,
			    <0x0a34 0x00000100>,
			    <0x0a38 0x011b00e0>,
			    <0x0a3c 0x00000166>;

			  ife2_reg_cfg = 
			    <0x0004 0x00030050>,
			    <0x0008 0x80000000>,
			    <0x000c 0x00000000>,
			    <0x0010 0x00000000>,
			    <0x0014 0x011001e0>,
			    <0x0018 0x80000000>,
			    <0x001c 0x000005a0>,
			    <0x0020 0x16248000>,
			    <0x0024 0x00000000>,
			    <0x0028 0x00000000>,
			    <0x002c 0x003c0000>,
			    <0x0030 0x00000280>,
			    <0x0034 0x00141000>,
			    <0x0038 0x00000000>,
			    <0x003c 0x00000000>,
			    <0x0040 0x00000000>,
			    <0x0044 0x100d0b08>,
			    <0x0048 0x00051248>,
			    <0x004c 0x100d0b08>,
			    <0x0050 0x00051248>,
			    <0x0054 0x00090909>,
			    <0x0058 0x00002020>,
			    <0x005c 0x100d0b08>,
			    <0x0060 0x00000016>,
			    <0x0064 0x00111110>,
			    <0x0068 0x100d0b08>,
			    <0x006c 0x00000016>,
			    <0x0070 0x00111110>,
			    <0x0074 0x100d0b08>,
			    <0x0078 0x00000016>,
			    <0x007c 0x00111110>,
			    <0x0080 0x0000837d>,
			    <0x0084 0x00072b14>,
			    <0x0088 0x00000002>,
			    <0x008c 0x0000837d>,
			    <0x0090 0x00068eea>,
			    <0x0094 0x00000002>,
			    <0x0098 0x00002db5>,
			    <0x009c 0x00000000>,
			    <0x00a0 0x00000000>,
			    <0x00a4 0x00000000>,
			    <0x00a8 0x00000000>,
			    <0x00ac 0x00000000>;

			};
		};
	};
};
